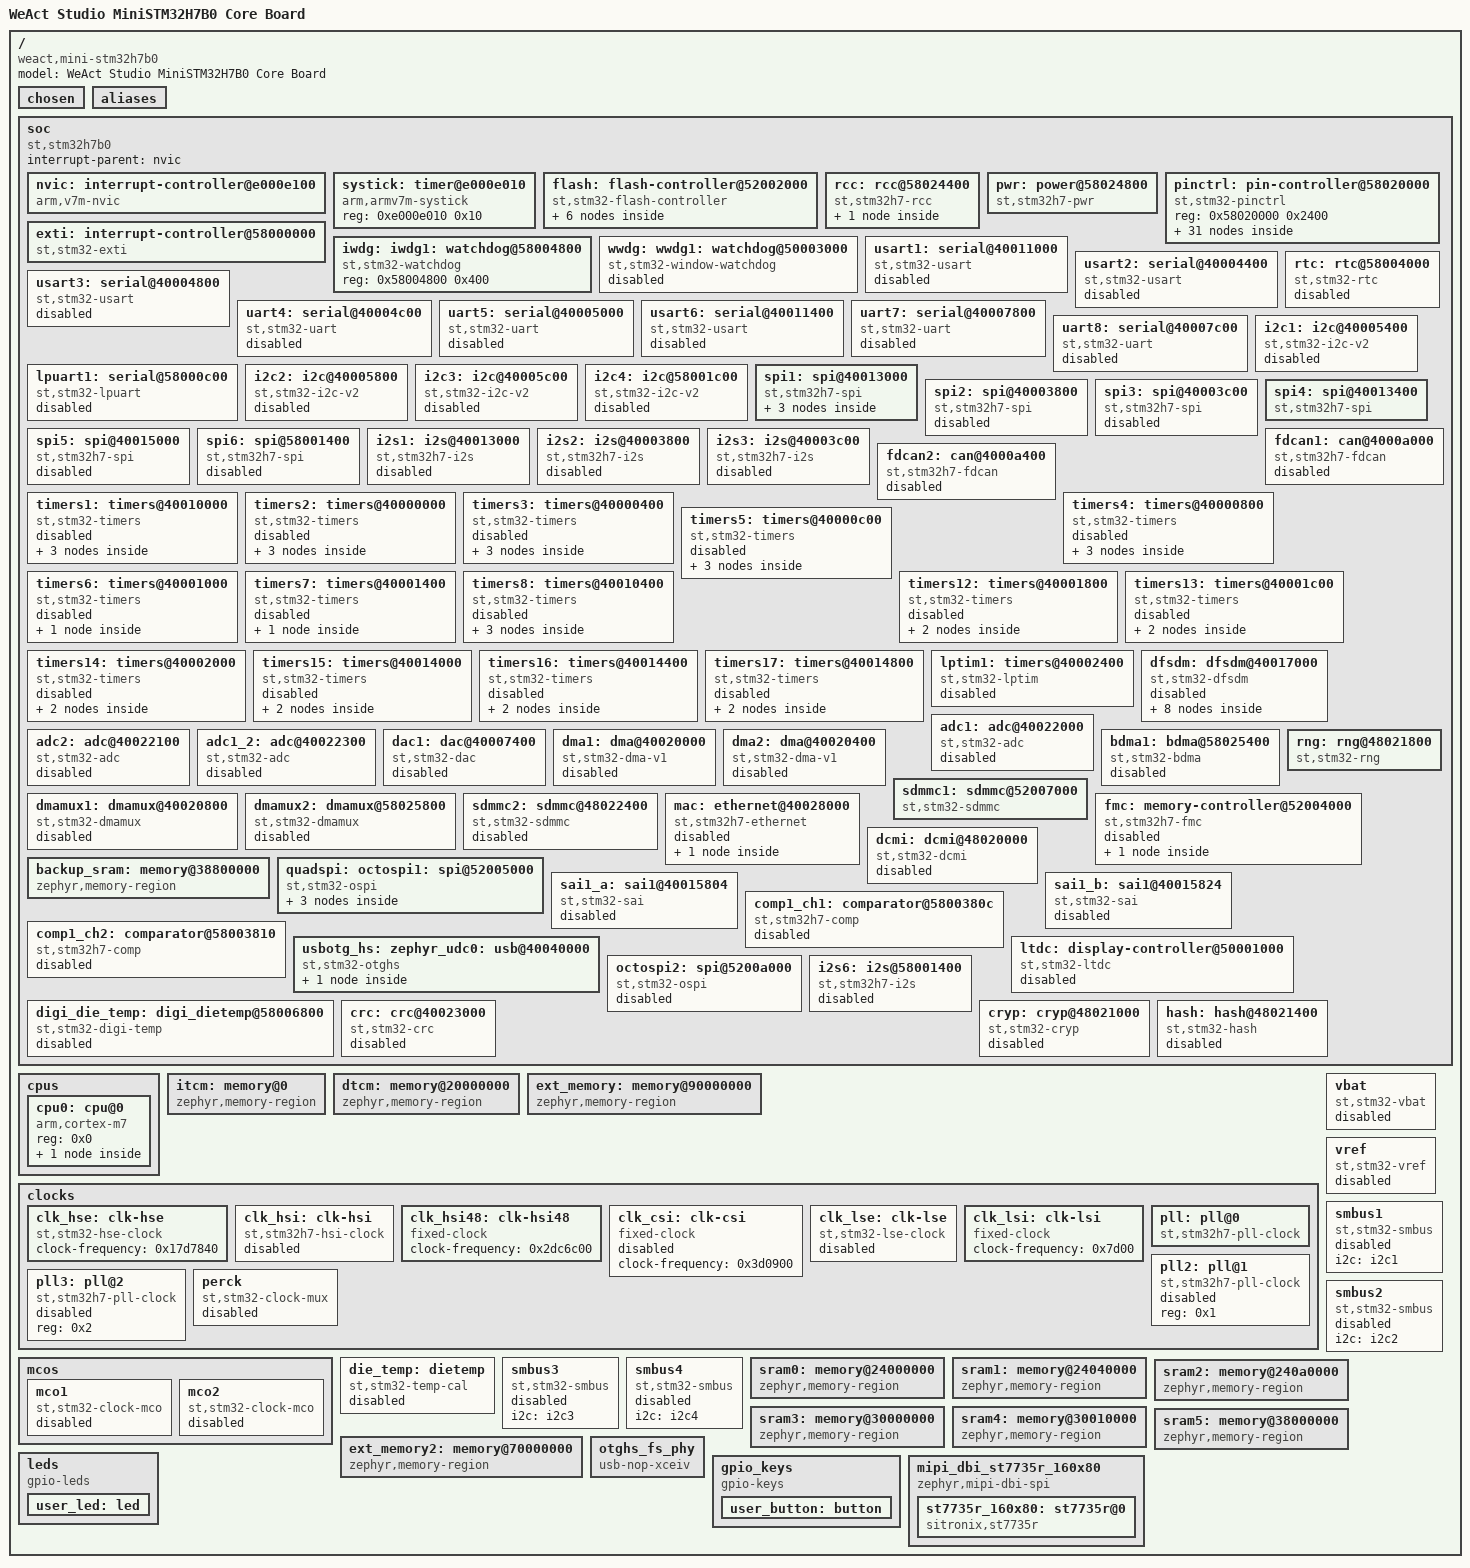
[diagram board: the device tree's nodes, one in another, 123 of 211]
/dts-v1/;

/* node '/' defined in zephyr/dts/common/skeleton.dtsi:9 */
/ {
	#address-cells = < 0x1 >;                        /* in zephyr/dts/common/skeleton.dtsi:10 */
	#size-cells = < 0x1 >;                           /* in zephyr/dts/common/skeleton.dtsi:11 */
	model = "WeAct Studio MiniSTM32H7B0 Core Board"; /* in zephyr/boards/weact/mini_stm32h7b0/mini_stm32h7b0.dts:14 */
	compatible = "weact,mini-stm32h7b0";             /* in zephyr/boards/weact/mini_stm32h7b0/mini_stm32h7b0.dts:15 */

	/* node '/chosen' defined in zephyr/dts/common/skeleton.dtsi:13 */
	chosen {
		zephyr,crc = &crc;                        /* in zephyr/dts/arm/st/h7/stm32h7.dtsi:29 */
		zephyr,entropy = &rng;                    /* in zephyr/dts/arm/st/h7/stm32h7.dtsi:30 */
		zephyr,flash-controller = &flash;         /* in zephyr/dts/arm/st/h7/stm32h7.dtsi:31 */
		zephyr,sram = &sram0;                     /* in zephyr/boards/weact/mini_stm32h7b0/mini_stm32h7b0.dts:18 */
		zephyr,flash = &flash0;                   /* in zephyr/boards/weact/mini_stm32h7b0/mini_stm32h7b0.dts:19 */
		zephyr,display = &st7735r_160x80;         /* in zephyr/boards/weact/mini_stm32h7b0/mini_stm32h7b0.dts:20 */
		zephyr,console = &board_cdc_acm_uart;     /* in zephyr/boards/common/usb/cdc_acm_serial.dtsi:9 */
		zephyr,shell-uart = &board_cdc_acm_uart;  /* in zephyr/boards/common/usb/cdc_acm_serial.dtsi:10 */
		zephyr,uart-mcumgr = &board_cdc_acm_uart; /* in zephyr/boards/common/usb/cdc_acm_serial.dtsi:11 */
		zephyr,bt-mon-uart = &board_cdc_acm_uart; /* in zephyr/boards/common/usb/cdc_acm_serial.dtsi:12 */
		zephyr,bt-c2h-uart = &board_cdc_acm_uart; /* in zephyr/boards/common/usb/cdc_acm_serial.dtsi:13 */
	};

	/* node '/aliases' defined in zephyr/dts/common/skeleton.dtsi:15 */
	aliases {
		led0 = &user_led;   /* in zephyr/boards/weact/mini_stm32h7b0/mini_stm32h7b0.dts:81 */
		sw0 = &user_button; /* in zephyr/boards/weact/mini_stm32h7b0/mini_stm32h7b0.dts:82 */
		watchdog0 = &iwdg;  /* in zephyr/boards/weact/mini_stm32h7b0/mini_stm32h7b0.dts:83 */
		sdhc0 = &sdmmc1;    /* in zephyr/boards/weact/mini_stm32h7b0/mini_stm32h7b0.dts:84 */
	};

	/* node '/soc' defined in zephyr/dts/arm/armv7-m.dtsi:6 */
	soc {
		#address-cells = < 0x1 >;     /* in zephyr/dts/arm/armv7-m.dtsi:7 */
		#size-cells = < 0x1 >;        /* in zephyr/dts/arm/armv7-m.dtsi:8 */
		interrupt-parent = < &nvic >; /* in zephyr/dts/arm/armv7-m.dtsi:10 */
		ranges;                       /* in zephyr/dts/arm/armv7-m.dtsi:11 */
		compatible = "st,stm32h7b0",
		             "st,stm32h7",
		             "simple-bus";    /* in zephyr/dts/arm/st/h7/stm32h7b0.dtsi:15 */

		/* node '/soc/interrupt-controller@e000e100' defined in zephyr/dts/arm/armv7-m.dtsi:13 */
		nvic: interrupt-controller@e000e100 {
			#address-cells = < 0x1 >;            /* in zephyr/dts/arm/armv7-m.dtsi:14 */
			compatible = "arm,v7m-nvic";         /* in zephyr/dts/arm/armv7-m.dtsi:15 */
			reg = < 0xe000e100 0xc00 >;          /* in zephyr/dts/arm/armv7-m.dtsi:16 */
			interrupt-controller;                /* in zephyr/dts/arm/armv7-m.dtsi:17 */
			#interrupt-cells = < 0x2 >;          /* in zephyr/dts/arm/armv7-m.dtsi:18 */
			arm,num-irq-priority-bits = < 0x4 >; /* in zephyr/dts/arm/st/h7/stm32h7.dtsi:1404 */
			phandle = < 0x1 >;                   /* in zephyr/dts/arm/armv7-m.dtsi:10 */
		};

		/* node '/soc/timer@e000e010' defined in zephyr/dts/arm/armv7-m.dtsi:21 */
		systick: timer@e000e010 {
			compatible = "arm,armv7m-systick"; /* in zephyr/dts/arm/armv7-m.dtsi:22 */
			reg = < 0xe000e010 0x10 >;         /* in zephyr/dts/arm/armv7-m.dtsi:23 */
		};

		/* node '/soc/flash-controller@52002000' defined in zephyr/dts/arm/st/h7/stm32h7.dtsi:162 */
		flash: flash-controller@52002000 {
			compatible = "st,stm32-flash-controller",
			             "st,stm32h7-flash-controller"; /* in zephyr/dts/arm/st/h7/stm32h7.dtsi:163 */
			reg = < 0x52002000 0x400 >;                 /* in zephyr/dts/arm/st/h7/stm32h7.dtsi:164 */
			interrupts = < 0x4 0x0 >;                   /* in zephyr/dts/arm/st/h7/stm32h7.dtsi:165 */
			#address-cells = < 0x1 >;                   /* in zephyr/dts/arm/st/h7/stm32h7.dtsi:167 */
			#size-cells = < 0x1 >;                      /* in zephyr/dts/arm/st/h7/stm32h7.dtsi:168 */
			ranges;                                     /* in zephyr/dts/arm/st/h7/stm32h7.dtsi:169 */

			/* node '/soc/flash-controller@52002000/flash@8000000' defined in zephyr/dts/arm/st/h7/stm32h7a3.dtsi:19 */
			flash0: flash@8000000 {
				compatible = "st,stm32-nv-flash",
				             "soc-nv-flash";        /* in zephyr/dts/arm/st/h7/stm32h7a3.dtsi:20 */
				#address-cells = < 0x1 >;           /* in zephyr/dts/arm/st/h7/stm32h7a3.dtsi:21 */
				#size-cells = < 0x1 >;              /* in zephyr/dts/arm/st/h7/stm32h7a3.dtsi:22 */
				write-block-size = < 0x10 >;        /* in zephyr/dts/arm/st/h7/stm32h7a3.dtsi:23 */
				erase-block-size = < 0x2000 >;      /* in zephyr/dts/arm/st/h7/stm32h7a3.dtsi:24 */
				max-erase-time = < 0x3 >;           /* in zephyr/dts/arm/st/h7/stm32h7a3.dtsi:26 */
				reg = < 0x8000000 0x20000 >;        /* in zephyr/dts/arm/st/h7/stm32h7b0Xb.dtsi:13 */
				ranges = < 0x0 0x8000000 0x20000 >; /* in zephyr/dts/arm/st/h7/stm32h7b0Xb.dtsi:14 */
			};

			/* node '/soc/flash-controller@52002000/flash@8fff800' defined in zephyr/dts/arm/st/h7/stm32h7a3.dtsi:36 */
			flash@8fff800 {
				compatible = "st,stm32-nvm-otp"; /* in zephyr/dts/arm/st/h7/stm32h7a3.dtsi:37 */
				reg = < 0x8fff800 0x200 >;       /* in zephyr/dts/arm/st/h7/stm32h7a3.dtsi:38 */

				/* node '/soc/flash-controller@52002000/flash@8fff800/nvmem-layout' defined in zephyr/dts/arm/st/h7/stm32h7a3.dtsi:40 */
				nvmem-layout {
					compatible = "fixed-layout"; /* in zephyr/dts/arm/st/h7/stm32h7a3.dtsi:41 */
					#address-cells = < 0x1 >;    /* in zephyr/dts/arm/st/h7/stm32h7a3.dtsi:42 */
					#size-cells = < 0x1 >;       /* in zephyr/dts/arm/st/h7/stm32h7a3.dtsi:43 */

					/* node '/soc/flash-controller@52002000/flash@8fff800/nvmem-layout/vrefint@10' defined in zephyr/dts/arm/st/h7/stm32h7a3.dtsi:45 */
					vrefint_otp: vrefint@10 {
						reg = < 0x10 0x2 >;          /* in zephyr/dts/arm/st/h7/stm32h7a3.dtsi:46 */
						#nvmem-cell-cells = < 0x0 >; /* in zephyr/dts/arm/st/h7/stm32h7a3.dtsi:47 */
						read-only;                   /* in zephyr/dts/arm/st/h7/stm32h7a3.dtsi:48 */
						phandle = < 0x23 >;          /* in zephyr/dts/arm/st/h7/stm32h7.dtsi:1364 */
					};

					/* node '/soc/flash-controller@52002000/flash@8fff800/nvmem-layout/ts-cal1@14' defined in zephyr/dts/arm/st/h7/stm32h7a3.dtsi:51 */
					ts_cal1_otp: ts-cal1@14 {
						reg = < 0x14 0x2 >;          /* in zephyr/dts/arm/st/h7/stm32h7a3.dtsi:52 */
						#nvmem-cell-cells = < 0x0 >; /* in zephyr/dts/arm/st/h7/stm32h7a3.dtsi:53 */
						read-only;                   /* in zephyr/dts/arm/st/h7/stm32h7a3.dtsi:54 */
						phandle = < 0x20 >;          /* in zephyr/dts/arm/st/h7/stm32h7.dtsi:1346 */
					};

					/* node '/soc/flash-controller@52002000/flash@8fff800/nvmem-layout/ts-cal2@18' defined in zephyr/dts/arm/st/h7/stm32h7a3.dtsi:57 */
					ts_cal2_otp: ts-cal2@18 {
						reg = < 0x18 0x2 >;          /* in zephyr/dts/arm/st/h7/stm32h7a3.dtsi:58 */
						#nvmem-cell-cells = < 0x0 >; /* in zephyr/dts/arm/st/h7/stm32h7a3.dtsi:59 */
						read-only;                   /* in zephyr/dts/arm/st/h7/stm32h7a3.dtsi:60 */
						phandle = < 0x21 >;          /* in zephyr/dts/arm/st/h7/stm32h7.dtsi:1346 */
					};
				};
			};
		};

		/* node '/soc/rcc@58024400' defined in zephyr/dts/arm/st/h7/stm32h7.dtsi:205 */
		rcc: rcc@58024400 {
			compatible = "st,stm32h7-rcc";    /* in zephyr/dts/arm/st/h7/stm32h7.dtsi:206 */
			#clock-cells = < 0x2 >;           /* in zephyr/dts/arm/st/h7/stm32h7.dtsi:207 */
			reg = < 0x58024400 0x400 >;       /* in zephyr/dts/arm/st/h7/stm32h7.dtsi:208 */
			clocks = < &pll >;                /* in zephyr/boards/weact/mini_stm32h7b0/mini_stm32h7b0.dts:112 */
			clock-frequency = < 0x10b07600 >; /* in zephyr/boards/weact/mini_stm32h7b0/mini_stm32h7b0.dts:113 */
			d1cpre = < 0x1 >;                 /* in zephyr/boards/weact/mini_stm32h7b0/mini_stm32h7b0.dts:114 */
			hpre = < 0x2 >;                   /* in zephyr/boards/weact/mini_stm32h7b0/mini_stm32h7b0.dts:115 */
			d1ppre = < 0x1 >;                 /* in zephyr/boards/weact/mini_stm32h7b0/mini_stm32h7b0.dts:116 */
			d2ppre1 = < 0x1 >;                /* in zephyr/boards/weact/mini_stm32h7b0/mini_stm32h7b0.dts:117 */
			d2ppre2 = < 0x1 >;                /* in zephyr/boards/weact/mini_stm32h7b0/mini_stm32h7b0.dts:118 */
			d3ppre = < 0x1 >;                 /* in zephyr/boards/weact/mini_stm32h7b0/mini_stm32h7b0.dts:119 */
			phandle = < 0x3 >;                /* in zephyr/dts/arm/st/h7/stm32h7.dtsi:231 */

			/* node '/soc/rcc@58024400/reset-controller' defined in zephyr/dts/arm/st/h7/stm32h7.dtsi:210 */
			rctl: reset-controller {
				compatible = "st,stm32-rcc-rctl"; /* in zephyr/dts/arm/st/h7/stm32h7.dtsi:211 */
				#reset-cells = < 0x1 >;           /* in zephyr/dts/arm/st/h7/stm32h7.dtsi:212 */
				phandle = < 0x4 >;                /* in zephyr/dts/arm/st/h7/stm32h7.dtsi:354 */
			};
		};

		/* node '/soc/power@58024800' defined in zephyr/dts/arm/st/h7/stm32h7.dtsi:216 */
		pwr: power@58024800 {
			compatible = "st,stm32h7-pwr"; /* in zephyr/dts/arm/st/h7/stm32h7.dtsi:221 */
			reg = < 0x58024800 0x400 >;    /* in zephyr/dts/arm/st/h7/stm32h7.dtsi:222 */
			power-supply = "ldo";          /* in zephyr/boards/weact/mini_stm32h7b0/mini_stm32h7b0.dts:123 */
		};

		/* node '/soc/interrupt-controller@58000000' defined in zephyr/dts/arm/st/h7/stm32h7.dtsi:225 */
		exti: interrupt-controller@58000000 {
			compatible = "st,stm32-exti";  /* in zephyr/dts/arm/st/h7/stm32h7.dtsi:226 */
			interrupt-controller;          /* in zephyr/dts/arm/st/h7/stm32h7.dtsi:227 */
			#interrupt-cells = < 0x1 >;    /* in zephyr/dts/arm/st/h7/stm32h7.dtsi:228 */
			#address-cells = < 0x0 >;      /* in zephyr/dts/arm/st/h7/stm32h7.dtsi:229 */
			reg = < 0x58000000 0x400 >;    /* in zephyr/dts/arm/st/h7/stm32h7.dtsi:230 */
			clocks = < &rcc 0xf4 0x2 >;    /* in zephyr/dts/arm/st/h7/stm32h7.dtsi:231 */
			num-lines = < 0x60 >;          /* in zephyr/dts/arm/st/h7/stm32h7.dtsi:232 */
			interrupts = < 0x6 0x0 >,
			             < 0x7 0x0 >,
			             < 0x8 0x0 >,
			             < 0x9 0x0 >,
			             < 0xa 0x0 >,
			             < 0x17 0x0 >,
			             < 0x28 0x0 >;     /* in zephyr/dts/arm/st/h7/stm32h7.dtsi:233 */
			interrupt-names = "line0",
			                  "line1",
			                  "line2",
			                  "line3",
			                  "line4",
			                  "line5-9",
			                  "line10-15"; /* in zephyr/dts/arm/st/h7/stm32h7.dtsi:235 */
			line-ranges = < 0x0 0x1 >,
			              < 0x1 0x1 >,
			              < 0x2 0x1 >,
			              < 0x3 0x1 >,
			              < 0x4 0x1 >,
			              < 0x5 0x5 >,
			              < 0xa 0x6 >;     /* in zephyr/dts/arm/st/h7/stm32h7.dtsi:237 */
		};

		/* node '/soc/pin-controller@58020000' defined in zephyr/dts/arm/st/h7/stm32h7.dtsi:241 */
		pinctrl: pin-controller@58020000 {
			compatible = "st,stm32-pinctrl"; /* in zephyr/dts/arm/st/h7/stm32h7.dtsi:242 */
			#address-cells = < 0x1 >;        /* in zephyr/dts/arm/st/h7/stm32h7.dtsi:243 */
			#size-cells = < 0x1 >;           /* in zephyr/dts/arm/st/h7/stm32h7.dtsi:244 */
			reg = < 0x58020000 0x2400 >;     /* in zephyr/dts/arm/st/h7/stm32h7.dtsi:245 */

			/* node '/soc/pin-controller@58020000/gpio@58020000' defined in zephyr/dts/arm/st/h7/stm32h7.dtsi:247 */
			gpioa: gpio@58020000 {
				compatible = "st,stm32-gpio"; /* in zephyr/dts/arm/st/h7/stm32h7.dtsi:248 */
				gpio-controller;              /* in zephyr/dts/arm/st/h7/stm32h7.dtsi:249 */
				#gpio-cells = < 0x2 >;        /* in zephyr/dts/arm/st/h7/stm32h7.dtsi:250 */
				reg = < 0x58020000 0x400 >;   /* in zephyr/dts/arm/st/h7/stm32h7.dtsi:251 */
				clocks = < &rcc 0xe0 0x1 >;   /* in zephyr/dts/arm/st/h7/stm32h7.dtsi:252 */
			};

			/* node '/soc/pin-controller@58020000/gpio@58020400' defined in zephyr/dts/arm/st/h7/stm32h7.dtsi:255 */
			gpiob: gpio@58020400 {
				compatible = "st,stm32-gpio"; /* in zephyr/dts/arm/st/h7/stm32h7.dtsi:256 */
				gpio-controller;              /* in zephyr/dts/arm/st/h7/stm32h7.dtsi:257 */
				#gpio-cells = < 0x2 >;        /* in zephyr/dts/arm/st/h7/stm32h7.dtsi:258 */
				reg = < 0x58020400 0x400 >;   /* in zephyr/dts/arm/st/h7/stm32h7.dtsi:259 */
				clocks = < &rcc 0xe0 0x2 >;   /* in zephyr/dts/arm/st/h7/stm32h7.dtsi:260 */
			};

			/* node '/soc/pin-controller@58020000/gpio@58020800' defined in zephyr/dts/arm/st/h7/stm32h7.dtsi:263 */
			gpioc: gpio@58020800 {
				compatible = "st,stm32-gpio"; /* in zephyr/dts/arm/st/h7/stm32h7.dtsi:264 */
				gpio-controller;              /* in zephyr/dts/arm/st/h7/stm32h7.dtsi:265 */
				#gpio-cells = < 0x2 >;        /* in zephyr/dts/arm/st/h7/stm32h7.dtsi:266 */
				reg = < 0x58020800 0x400 >;   /* in zephyr/dts/arm/st/h7/stm32h7.dtsi:267 */
				clocks = < &rcc 0xe0 0x4 >;   /* in zephyr/dts/arm/st/h7/stm32h7.dtsi:268 */
				phandle = < 0x28 >;           /* in zephyr/boards/weact/mini_stm32h7b0/mini_stm32h7b0.dts:37 */
			};

			/* node '/soc/pin-controller@58020000/gpio@58020c00' defined in zephyr/dts/arm/st/h7/stm32h7.dtsi:271 */
			gpiod: gpio@58020c00 {
				compatible = "st,stm32-gpio"; /* in zephyr/dts/arm/st/h7/stm32h7.dtsi:272 */
				gpio-controller;              /* in zephyr/dts/arm/st/h7/stm32h7.dtsi:273 */
				#gpio-cells = < 0x2 >;        /* in zephyr/dts/arm/st/h7/stm32h7.dtsi:274 */
				reg = < 0x58020c00 0x400 >;   /* in zephyr/dts/arm/st/h7/stm32h7.dtsi:275 */
				clocks = < &rcc 0xe0 0x8 >;   /* in zephyr/dts/arm/st/h7/stm32h7.dtsi:276 */
				phandle = < 0x8 >;            /* in zephyr/boards/weact/mini_stm32h7b0/mini_stm32h7b0.dts:175 */
			};

			/* node '/soc/pin-controller@58020000/gpio@58021000' defined in zephyr/dts/arm/st/h7/stm32h7.dtsi:279 */
			gpioe: gpio@58021000 {
				compatible = "st,stm32-gpio"; /* in zephyr/dts/arm/st/h7/stm32h7.dtsi:280 */
				gpio-controller;              /* in zephyr/dts/arm/st/h7/stm32h7.dtsi:281 */
				#gpio-cells = < 0x2 >;        /* in zephyr/dts/arm/st/h7/stm32h7.dtsi:282 */
				reg = < 0x58021000 0x400 >;   /* in zephyr/dts/arm/st/h7/stm32h7.dtsi:283 */
				clocks = < &rcc 0xe0 0x10 >;  /* in zephyr/dts/arm/st/h7/stm32h7.dtsi:284 */
				status = "okay";              /* in zephyr/boards/weact/mini_stm32h7b0/mini_stm32h7b0.dts:204 */
				phandle = < 0xb >;            /* in zephyr/boards/weact/mini_stm32h7b0/mini_stm32h7b0.dts:215 */

				/* node '/soc/pin-controller@58020000/gpio@58021000/lcd_led' defined in zephyr/boards/weact/mini_stm32h7b0/mini_stm32h7b0.dts:206 */
				lcd_led {
					gpio-hog;            /* in zephyr/boards/weact/mini_stm32h7b0/mini_stm32h7b0.dts:207 */
					gpios = < 0xa 0x1 >; /* in zephyr/boards/weact/mini_stm32h7b0/mini_stm32h7b0.dts:208 */
					output-high;         /* in zephyr/boards/weact/mini_stm32h7b0/mini_stm32h7b0.dts:209 */
				};
			};

			/* node '/soc/pin-controller@58020000/gpio@58021400' defined in zephyr/dts/arm/st/h7/stm32h7.dtsi:287 */
			gpiof: gpio@58021400 {
				compatible = "st,stm32-gpio"; /* in zephyr/dts/arm/st/h7/stm32h7.dtsi:288 */
				gpio-controller;              /* in zephyr/dts/arm/st/h7/stm32h7.dtsi:289 */
				#gpio-cells = < 0x2 >;        /* in zephyr/dts/arm/st/h7/stm32h7.dtsi:290 */
				reg = < 0x58021400 0x400 >;   /* in zephyr/dts/arm/st/h7/stm32h7.dtsi:291 */
				clocks = < &rcc 0xe0 0x20 >;  /* in zephyr/dts/arm/st/h7/stm32h7.dtsi:292 */
			};

			/* node '/soc/pin-controller@58020000/gpio@58021800' defined in zephyr/dts/arm/st/h7/stm32h7.dtsi:295 */
			gpiog: gpio@58021800 {
				compatible = "st,stm32-gpio"; /* in zephyr/dts/arm/st/h7/stm32h7.dtsi:296 */
				gpio-controller;              /* in zephyr/dts/arm/st/h7/stm32h7.dtsi:297 */
				#gpio-cells = < 0x2 >;        /* in zephyr/dts/arm/st/h7/stm32h7.dtsi:298 */
				reg = < 0x58021800 0x400 >;   /* in zephyr/dts/arm/st/h7/stm32h7.dtsi:299 */
				clocks = < &rcc 0xe0 0x40 >;  /* in zephyr/dts/arm/st/h7/stm32h7.dtsi:300 */
			};

			/* node '/soc/pin-controller@58020000/gpio@58021c00' defined in zephyr/dts/arm/st/h7/stm32h7.dtsi:303 */
			gpioh: gpio@58021c00 {
				compatible = "st,stm32-gpio"; /* in zephyr/dts/arm/st/h7/stm32h7.dtsi:304 */
				gpio-controller;              /* in zephyr/dts/arm/st/h7/stm32h7.dtsi:305 */
				#gpio-cells = < 0x2 >;        /* in zephyr/dts/arm/st/h7/stm32h7.dtsi:306 */
				reg = < 0x58021c00 0x400 >;   /* in zephyr/dts/arm/st/h7/stm32h7.dtsi:307 */
				clocks = < &rcc 0xe0 0x80 >;  /* in zephyr/dts/arm/st/h7/stm32h7.dtsi:308 */
			};

			/* node '/soc/pin-controller@58020000/gpio@58022000' defined in zephyr/dts/arm/st/h7/stm32h7.dtsi:311 */
			gpioi: gpio@58022000 {
				compatible = "st,stm32-gpio"; /* in zephyr/dts/arm/st/h7/stm32h7.dtsi:312 */
				gpio-controller;              /* in zephyr/dts/arm/st/h7/stm32h7.dtsi:313 */
				#gpio-cells = < 0x2 >;        /* in zephyr/dts/arm/st/h7/stm32h7.dtsi:314 */
				reg = < 0x58022000 0x400 >;   /* in zephyr/dts/arm/st/h7/stm32h7.dtsi:315 */
				clocks = < &rcc 0xe0 0x100 >; /* in zephyr/dts/arm/st/h7/stm32h7.dtsi:316 */
			};

			/* node '/soc/pin-controller@58020000/gpio@58022400' defined in zephyr/dts/arm/st/h7/stm32h7.dtsi:319 */
			gpioj: gpio@58022400 {
				compatible = "st,stm32-gpio"; /* in zephyr/dts/arm/st/h7/stm32h7.dtsi:320 */
				gpio-controller;              /* in zephyr/dts/arm/st/h7/stm32h7.dtsi:321 */
				#gpio-cells = < 0x2 >;        /* in zephyr/dts/arm/st/h7/stm32h7.dtsi:322 */
				reg = < 0x58022400 0x400 >;   /* in zephyr/dts/arm/st/h7/stm32h7.dtsi:323 */
				clocks = < &rcc 0xe0 0x200 >; /* in zephyr/dts/arm/st/h7/stm32h7.dtsi:324 */
			};

			/* node '/soc/pin-controller@58020000/gpio@58022800' defined in zephyr/dts/arm/st/h7/stm32h7.dtsi:327 */
			gpiok: gpio@58022800 {
				compatible = "st,stm32-gpio"; /* in zephyr/dts/arm/st/h7/stm32h7.dtsi:328 */
				gpio-controller;              /* in zephyr/dts/arm/st/h7/stm32h7.dtsi:329 */
				#gpio-cells = < 0x2 >;        /* in zephyr/dts/arm/st/h7/stm32h7.dtsi:330 */
				reg = < 0x58022800 0x400 >;   /* in zephyr/dts/arm/st/h7/stm32h7.dtsi:331 */
				clocks = < &rcc 0xe0 0x400 >; /* in zephyr/dts/arm/st/h7/stm32h7.dtsi:332 */
			};

			/* node '/soc/pin-controller@58020000/octospim_p1_clk_pb2' defined in modules/hal/stm32/dts/st/h7/stm32h7b0vbtx-pinctrl.dtsi:1997 */
			octospim_p1_clk_pb2: octospim_p1_clk_pb2 {
				pinmux = < 0x249 >;            /* in modules/hal/stm32/dts/st/h7/stm32h7b0vbtx-pinctrl.dtsi:1998 */
				slew-rate = "very-high-speed"; /* in modules/hal/stm32/dts/st/h7/stm32h7b0vbtx-pinctrl.dtsi:1999 */
				phandle = < 0x14 >;            /* in zephyr/boards/weact/mini_stm32h7b0/mini_stm32h7b0.dts:146 */
			};

			/* node '/soc/pin-controller@58020000/octospim_p1_ncs_pb6' defined in modules/hal/stm32/dts/st/h7/stm32h7b0vbtx-pinctrl.dtsi:2007 */
			octospim_p1_ncs_pb6: octospim_p1_ncs_pb6 {
				pinmux = < 0x2ca >;            /* in modules/hal/stm32/dts/st/h7/stm32h7b0vbtx-pinctrl.dtsi:2008 */
				slew-rate = "very-high-speed"; /* in modules/hal/stm32/dts/st/h7/stm32h7b0vbtx-pinctrl.dtsi:2009 */
				phandle = < 0x15 >;            /* in zephyr/boards/weact/mini_stm32h7b0/mini_stm32h7b0.dts:146 */
			};

			/* node '/soc/pin-controller@58020000/octospim_p1_io0_pd11' defined in modules/hal/stm32/dts/st/h7/stm32h7b0vbtx-pinctrl.dtsi:2087 */
			octospim_p1_io0_pd11: octospim_p1_io0_pd11 {
				pinmux = < 0x769 >;            /* in modules/hal/stm32/dts/st/h7/stm32h7b0vbtx-pinctrl.dtsi:2088 */
				slew-rate = "very-high-speed"; /* in modules/hal/stm32/dts/st/h7/stm32h7b0vbtx-pinctrl.dtsi:2089 */
				phandle = < 0x16 >;            /* in zephyr/boards/weact/mini_stm32h7b0/mini_stm32h7b0.dts:146 */
			};

			/* node '/soc/pin-controller@58020000/octospim_p1_io1_pd12' defined in modules/hal/stm32/dts/st/h7/stm32h7b0vbtx-pinctrl.dtsi:2092 */
			octospim_p1_io1_pd12: octospim_p1_io1_pd12 {
				pinmux = < 0x789 >;            /* in modules/hal/stm32/dts/st/h7/stm32h7b0vbtx-pinctrl.dtsi:2093 */
				slew-rate = "very-high-speed"; /* in modules/hal/stm32/dts/st/h7/stm32h7b0vbtx-pinctrl.dtsi:2094 */
				phandle = < 0x17 >;            /* in zephyr/boards/weact/mini_stm32h7b0/mini_stm32h7b0.dts:146 */
			};

			/* node '/soc/pin-controller@58020000/octospim_p1_io3_pd13' defined in modules/hal/stm32/dts/st/h7/stm32h7b0vbtx-pinctrl.dtsi:2097 */
			octospim_p1_io3_pd13: octospim_p1_io3_pd13 {
				pinmux = < 0x7a9 >;            /* in modules/hal/stm32/dts/st/h7/stm32h7b0vbtx-pinctrl.dtsi:2098 */
				slew-rate = "very-high-speed"; /* in modules/hal/stm32/dts/st/h7/stm32h7b0vbtx-pinctrl.dtsi:2099 */
				phandle = < 0x19 >;            /* in zephyr/boards/weact/mini_stm32h7b0/mini_stm32h7b0.dts:146 */
			};

			/* node '/soc/pin-controller@58020000/octospim_p1_io2_pe2' defined in modules/hal/stm32/dts/st/h7/stm32h7b0vbtx-pinctrl.dtsi:2102 */
			octospim_p1_io2_pe2: octospim_p1_io2_pe2 {
				pinmux = < 0x849 >;            /* in modules/hal/stm32/dts/st/h7/stm32h7b0vbtx-pinctrl.dtsi:2103 */
				slew-rate = "very-high-speed"; /* in modules/hal/stm32/dts/st/h7/stm32h7b0vbtx-pinctrl.dtsi:2104 */
				phandle = < 0x18 >;            /* in zephyr/boards/weact/mini_stm32h7b0/mini_stm32h7b0.dts:146 */
			};

			/* node '/soc/pin-controller@58020000/sdmmc1_d0_pc8' defined in modules/hal/stm32/dts/st/h7/stm32h7b0vbtx-pinctrl.dtsi:2352 */
			sdmmc1_d0_pc8: sdmmc1_d0_pc8 {
				pinmux = < 0x50c >;            /* in modules/hal/stm32/dts/st/h7/stm32h7b0vbtx-pinctrl.dtsi:2353 */
				bias-pull-up;                  /* in modules/hal/stm32/dts/st/h7/stm32h7b0vbtx-pinctrl.dtsi:2354 */
				slew-rate = "very-high-speed"; /* in modules/hal/stm32/dts/st/h7/stm32h7b0vbtx-pinctrl.dtsi:2355 */
				phandle = < 0xd >;             /* in zephyr/boards/weact/mini_stm32h7b0/mini_stm32h7b0.dts:127 */
			};

			/* node '/soc/pin-controller@58020000/sdmmc1_d1_pc9' defined in modules/hal/stm32/dts/st/h7/stm32h7b0vbtx-pinctrl.dtsi:2358 */
			sdmmc1_d1_pc9: sdmmc1_d1_pc9 {
				pinmux = < 0x52c >;            /* in modules/hal/stm32/dts/st/h7/stm32h7b0vbtx-pinctrl.dtsi:2359 */
				bias-pull-up;                  /* in modules/hal/stm32/dts/st/h7/stm32h7b0vbtx-pinctrl.dtsi:2360 */
				slew-rate = "very-high-speed"; /* in modules/hal/stm32/dts/st/h7/stm32h7b0vbtx-pinctrl.dtsi:2361 */
				phandle = < 0xe >;             /* in zephyr/boards/weact/mini_stm32h7b0/mini_stm32h7b0.dts:127 */
			};

			/* node '/soc/pin-controller@58020000/sdmmc1_d2_pc10' defined in modules/hal/stm32/dts/st/h7/stm32h7b0vbtx-pinctrl.dtsi:2364 */
			sdmmc1_d2_pc10: sdmmc1_d2_pc10 {
				pinmux = < 0x54c >;            /* in modules/hal/stm32/dts/st/h7/stm32h7b0vbtx-pinctrl.dtsi:2365 */
				bias-pull-up;                  /* in modules/hal/stm32/dts/st/h7/stm32h7b0vbtx-pinctrl.dtsi:2366 */
				slew-rate = "very-high-speed"; /* in modules/hal/stm32/dts/st/h7/stm32h7b0vbtx-pinctrl.dtsi:2367 */
				phandle = < 0xf >;             /* in zephyr/boards/weact/mini_stm32h7b0/mini_stm32h7b0.dts:127 */
			};

			/* node '/soc/pin-controller@58020000/sdmmc1_d3_pc11' defined in modules/hal/stm32/dts/st/h7/stm32h7b0vbtx-pinctrl.dtsi:2370 */
			sdmmc1_d3_pc11: sdmmc1_d3_pc11 {
				pinmux = < 0x56c >;            /* in modules/hal/stm32/dts/st/h7/stm32h7b0vbtx-pinctrl.dtsi:2371 */
				bias-pull-up;                  /* in modules/hal/stm32/dts/st/h7/stm32h7b0vbtx-pinctrl.dtsi:2372 */
				slew-rate = "very-high-speed"; /* in modules/hal/stm32/dts/st/h7/stm32h7b0vbtx-pinctrl.dtsi:2373 */
				phandle = < 0x10 >;            /* in zephyr/boards/weact/mini_stm32h7b0/mini_stm32h7b0.dts:127 */
			};

			/* node '/soc/pin-controller@58020000/sdmmc1_ck_pc12' defined in modules/hal/stm32/dts/st/h7/stm32h7b0vbtx-pinctrl.dtsi:2376 */
			sdmmc1_ck_pc12: sdmmc1_ck_pc12 {
				pinmux = < 0x58c >;            /* in modules/hal/stm32/dts/st/h7/stm32h7b0vbtx-pinctrl.dtsi:2377 */
				bias-pull-up;                  /* in modules/hal/stm32/dts/st/h7/stm32h7b0vbtx-pinctrl.dtsi:2378 */
				slew-rate = "very-high-speed"; /* in modules/hal/stm32/dts/st/h7/stm32h7b0vbtx-pinctrl.dtsi:2379 */
				phandle = < 0x11 >;            /* in zephyr/boards/weact/mini_stm32h7b0/mini_stm32h7b0.dts:127 */
			};

			/* node '/soc/pin-controller@58020000/sdmmc1_cmd_pd2' defined in modules/hal/stm32/dts/st/h7/stm32h7b0vbtx-pinctrl.dtsi:2382 */
			sdmmc1_cmd_pd2: sdmmc1_cmd_pd2 {
				pinmux = < 0x64c >;            /* in modules/hal/stm32/dts/st/h7/stm32h7b0vbtx-pinctrl.dtsi:2383 */
				bias-pull-up;                  /* in modules/hal/stm32/dts/st/h7/stm32h7b0vbtx-pinctrl.dtsi:2384 */
				slew-rate = "very-high-speed"; /* in modules/hal/stm32/dts/st/h7/stm32h7b0vbtx-pinctrl.dtsi:2385 */
				phandle = < 0x12 >;            /* in zephyr/boards/weact/mini_stm32h7b0/mini_stm32h7b0.dts:127 */
			};

			/* node '/soc/pin-controller@58020000/spi1_miso_pb4' defined in modules/hal/stm32/dts/st/h7/stm32h7b0vbtx-pinctrl.dtsi:2468 */
			spi1_miso_pb4: spi1_miso_pb4 {
				pinmux = < 0x285 >;            /* in modules/hal/stm32/dts/st/h7/stm32h7b0vbtx-pinctrl.dtsi:2469 */
				bias-pull-down;                /* in modules/hal/stm32/dts/st/h7/stm32h7b0vbtx-pinctrl.dtsi:2470 */
				slew-rate = "very-high-speed"; /* in modules/hal/stm32/dts/st/h7/stm32h7b0vbtx-pinctrl.dtsi:2471 */
				phandle = < 0x6 >;             /* in zephyr/boards/weact/mini_stm32h7b0/mini_stm32h7b0.dts:174 */
			};

			/* node '/soc/pin-controller@58020000/spi1_mosi_pd7' defined in modules/hal/stm32/dts/st/h7/stm32h7b0vbtx-pinctrl.dtsi:2536 */
			spi1_mosi_pd7: spi1_mosi_pd7 {
				pinmux = < 0x6e5 >;            /* in modules/hal/stm32/dts/st/h7/stm32h7b0vbtx-pinctrl.dtsi:2537 */
				bias-pull-down;                /* in modules/hal/stm32/dts/st/h7/stm32h7b0vbtx-pinctrl.dtsi:2538 */
				slew-rate = "very-high-speed"; /* in modules/hal/stm32/dts/st/h7/stm32h7b0vbtx-pinctrl.dtsi:2539 */
				phandle = < 0x7 >;             /* in zephyr/boards/weact/mini_stm32h7b0/mini_stm32h7b0.dts:174 */
			};

			/* node '/soc/pin-controller@58020000/spi4_mosi_pe14' defined in modules/hal/stm32/dts/st/h7/stm32h7b0vbtx-pinctrl.dtsi:2590 */
			spi4_mosi_pe14: spi4_mosi_pe14 {
				pinmux = < 0x9c5 >;            /* in modules/hal/stm32/dts/st/h7/stm32h7b0vbtx-pinctrl.dtsi:2591 */
				bias-pull-down;                /* in modules/hal/stm32/dts/st/h7/stm32h7b0vbtx-pinctrl.dtsi:2592 */
				slew-rate = "very-high-speed"; /* in modules/hal/stm32/dts/st/h7/stm32h7b0vbtx-pinctrl.dtsi:2593 */
				phandle = < 0xa >;             /* in zephyr/boards/weact/mini_stm32h7b0/mini_stm32h7b0.dts:214 */
			};

			/* node '/soc/pin-controller@58020000/spi1_sck_pb3' defined in modules/hal/stm32/dts/st/h7/stm32h7b0vbtx-pinctrl.dtsi:2696 */
			spi1_sck_pb3: spi1_sck_pb3 {
				pinmux = < 0x265 >;            /* in modules/hal/stm32/dts/st/h7/stm32h7b0vbtx-pinctrl.dtsi:2697 */
				bias-pull-down;                /* in modules/hal/stm32/dts/st/h7/stm32h7b0vbtx-pinctrl.dtsi:2698 */
				slew-rate = "very-high-speed"; /* in modules/hal/stm32/dts/st/h7/stm32h7b0vbtx-pinctrl.dtsi:2699 */
				phandle = < 0x5 >;             /* in zephyr/boards/weact/mini_stm32h7b0/mini_stm32h7b0.dts:174 */
			};

			/* node '/soc/pin-controller@58020000/spi4_sck_pe12' defined in modules/hal/stm32/dts/st/h7/stm32h7b0vbtx-pinctrl.dtsi:2750 */
			spi4_sck_pe12: spi4_sck_pe12 {
				pinmux = < 0x985 >;            /* in modules/hal/stm32/dts/st/h7/stm32h7b0vbtx-pinctrl.dtsi:2751 */
				bias-pull-down;                /* in modules/hal/stm32/dts/st/h7/stm32h7b0vbtx-pinctrl.dtsi:2752 */
				slew-rate = "very-high-speed"; /* in modules/hal/stm32/dts/st/h7/stm32h7b0vbtx-pinctrl.dtsi:2753 */
				phandle = < 0x9 >;             /* in zephyr/boards/weact/mini_stm32h7b0/mini_stm32h7b0.dts:214 */
			};

			/* node '/soc/pin-controller@58020000/usb_otg_hs_dm_pa11' defined in modules/hal/stm32/dts/st/h7/stm32h7b0vbtx-pinctrl.dtsi:3543 */
			usb_otg_hs_dm_pa11: usb_otg_hs_dm_pa11 {
				pinmux = < 0x170 >; /* in modules/hal/stm32/dts/st/h7/stm32h7b0vbtx-pinctrl.dtsi:3544 */
				phandle = < 0x1c >; /* in zephyr/boards/weact/mini_stm32h7b0/mini_stm32h7b0.dts:137 */
			};

			/* node '/soc/pin-controller@58020000/usb_otg_hs_dp_pa12' defined in modules/hal/stm32/dts/st/h7/stm32h7b0vbtx-pinctrl.dtsi:3547 */
			usb_otg_hs_dp_pa12: usb_otg_hs_dp_pa12 {
				pinmux = < 0x190 >; /* in modules/hal/stm32/dts/st/h7/stm32h7b0vbtx-pinctrl.dtsi:3548 */
				phandle = < 0x1d >; /* in zephyr/boards/weact/mini_stm32h7b0/mini_stm32h7b0.dts:137 */
			};
		};

		/* node '/soc/watchdog@58004800' defined in zephyr/dts/arm/st/h7/stm32h7.dtsi:336 */
		iwdg: iwdg1: watchdog@58004800 {
			compatible = "st,stm32-watchdog"; /* in zephyr/dts/arm/st/h7/stm32h7.dtsi:337 */
			reg = < 0x58004800 0x400 >;       /* in zephyr/dts/arm/st/h7/stm32h7.dtsi:338 */
			status = "okay";                  /* in zephyr/boards/weact/mini_stm32h7b0/mini_stm32h7b0.dts:229 */
		};

		/* node '/soc/watchdog@50003000' defined in zephyr/dts/arm/st/h7/stm32h7.dtsi:342 */
		wwdg: wwdg1: watchdog@50003000 {
			compatible = "st,stm32-window-watchdog"; /* in zephyr/dts/arm/st/h7/stm32h7.dtsi:343 */
			reg = < 0x50003000 0x1000 >;             /* in zephyr/dts/arm/st/h7/stm32h7.dtsi:344 */
			clocks = < &rcc 0xe4 0x40 >;             /* in zephyr/dts/arm/st/h7/stm32h7.dtsi:345 */
			interrupts = < 0x0 0x0 >;                /* in zephyr/dts/arm/st/h7/stm32h7.dtsi:346 */
			status = "disabled";                     /* in zephyr/dts/arm/st/h7/stm32h7.dtsi:347 */
		};

		/* node '/soc/serial@40011000' defined in zephyr/dts/arm/st/h7/stm32h7.dtsi:350 */
		usart1: serial@40011000 {
			compatible = "st,stm32-usart",
			             "st,stm32-uart";  /* in zephyr/dts/arm/st/h7/stm32h7.dtsi:351 */
			reg = < 0x40011000 0x400 >;    /* in zephyr/dts/arm/st/h7/stm32h7.dtsi:352 */
			clocks = < &rcc 0xf0 0x10 >;   /* in zephyr/dts/arm/st/h7/stm32h7.dtsi:353 */
			resets = < &rctl 0x1304 >;     /* in zephyr/dts/arm/st/h7/stm32h7.dtsi:354 */
			interrupts = < 0x25 0x0 >;     /* in zephyr/dts/arm/st/h7/stm32h7.dtsi:355 */
			status = "disabled";           /* in zephyr/dts/arm/st/h7/stm32h7.dtsi:356 */
		};

		/* node '/soc/serial@40004400' defined in zephyr/dts/arm/st/h7/stm32h7.dtsi:359 */
		usart2: serial@40004400 {
			compatible = "st,stm32-usart",
			             "st,stm32-uart";   /* in zephyr/dts/arm/st/h7/stm32h7.dtsi:360 */
			reg = < 0x40004400 0x400 >;     /* in zephyr/dts/arm/st/h7/stm32h7.dtsi:361 */
			clocks = < &rcc 0xe8 0x20000 >; /* in zephyr/dts/arm/st/h7/stm32h7.dtsi:362 */
			resets = < &rctl 0x1211 >;      /* in zephyr/dts/arm/st/h7/stm32h7.dtsi:363 */
			interrupts = < 0x26 0x0 >;      /* in zephyr/dts/arm/st/h7/stm32h7.dtsi:364 */
			status = "disabled";            /* in zephyr/dts/arm/st/h7/stm32h7.dtsi:365 */
		};

		/* node '/soc/serial@40004800' defined in zephyr/dts/arm/st/h7/stm32h7.dtsi:368 */
		usart3: serial@40004800 {
			compatible = "st,stm32-usart",
			             "st,stm32-uart";   /* in zephyr/dts/arm/st/h7/stm32h7.dtsi:369 */
			reg = < 0x40004800 0x400 >;     /* in zephyr/dts/arm/st/h7/stm32h7.dtsi:370 */
			clocks = < &rcc 0xe8 0x40000 >; /* in zephyr/dts/arm/st/h7/stm32h7.dtsi:371 */
			resets = < &rctl 0x1212 >;      /* in zephyr/dts/arm/st/h7/stm32h7.dtsi:372 */
			interrupts = < 0x27 0x0 >;      /* in zephyr/dts/arm/st/h7/stm32h7.dtsi:373 */
			status = "disabled";            /* in zephyr/dts/arm/st/h7/stm32h7.dtsi:374 */
		};

		/* node '/soc/serial@40004c00' defined in zephyr/dts/arm/st/h7/stm32h7.dtsi:377 */
		uart4: serial@40004c00 {
			compatible = "st,stm32-uart";   /* in zephyr/dts/arm/st/h7/stm32h7.dtsi:378 */
			reg = < 0x40004c00 0x400 >;     /* in zephyr/dts/arm/st/h7/stm32h7.dtsi:379 */
			clocks = < &rcc 0xe8 0x80000 >; /* in zephyr/dts/arm/st/h7/stm32h7.dtsi:380 */
			resets = < &rctl 0x1213 >;      /* in zephyr/dts/arm/st/h7/stm32h7.dtsi:381 */
			interrupts = < 0x34 0x0 >;      /* in zephyr/dts/arm/st/h7/stm32h7.dtsi:382 */
			status = "disabled";            /* in zephyr/dts/arm/st/h7/stm32h7.dtsi:383 */
		};

		/* node '/soc/serial@40005000' defined in zephyr/dts/arm/st/h7/stm32h7.dtsi:386 */
		uart5: serial@40005000 {
			compatible = "st,stm32-uart";    /* in zephyr/dts/arm/st/h7/stm32h7.dtsi:387 */
			reg = < 0x40005000 0x400 >;      /* in zephyr/dts/arm/st/h7/stm32h7.dtsi:388 */
			clocks = < &rcc 0xe8 0x100000 >; /* in zephyr/dts/arm/st/h7/stm32h7.dtsi:389 */
			resets = < &rctl 0x1214 >;       /* in zephyr/dts/arm/st/h7/stm32h7.dtsi:390 */
			interrupts = < 0x35 0x0 >;       /* in zephyr/dts/arm/st/h7/stm32h7.dtsi:391 */
			status = "disabled";             /* in zephyr/dts/arm/st/h7/stm32h7.dtsi:392 */
		};

		/* node '/soc/serial@40011400' defined in zephyr/dts/arm/st/h7/stm32h7.dtsi:395 */
		usart6: serial@40011400 {
			compatible = "st,stm32-usart",
			             "st,stm32-uart";  /* in zephyr/dts/arm/st/h7/stm32h7.dtsi:396 */
			reg = < 0x40011400 0x400 >;    /* in zephyr/dts/arm/st/h7/stm32h7.dtsi:397 */
			clocks = < &rcc 0xf0 0x20 >;   /* in zephyr/dts/arm/st/h7/stm32h7.dtsi:398 */
			resets = < &rctl 0x1305 >;     /* in zephyr/dts/arm/st/h7/stm32h7.dtsi:399 */
			interrupts = < 0x47 0x0 >;     /* in zephyr/dts/arm/st/h7/stm32h7.dtsi:400 */
			status = "disabled";           /* in zephyr/dts/arm/st/h7/stm32h7.dtsi:401 */
		};

		/* node '/soc/serial@40007800' defined in zephyr/dts/arm/st/h7/stm32h7.dtsi:404 */
		uart7: serial@40007800 {
			compatible = "st,stm32-uart";      /* in zephyr/dts/arm/st/h7/stm32h7.dtsi:405 */
			reg = < 0x40007800 0x400 >;        /* in zephyr/dts/arm/st/h7/stm32h7.dtsi:406 */
			clocks = < &rcc 0xe8 0x40000000 >; /* in zephyr/dts/arm/st/h7/stm32h7.dtsi:407 */
			resets = < &rctl 0x121e >;         /* in zephyr/dts/arm/st/h7/stm32h7.dtsi:408 */
			interrupts = < 0x52 0x0 >;         /* in zephyr/dts/arm/st/h7/stm32h7.dtsi:409 */
			status = "disabled";               /* in zephyr/dts/arm/st/h7/stm32h7.dtsi:410 */
		};

		/* node '/soc/serial@40007c00' defined in zephyr/dts/arm/st/h7/stm32h7.dtsi:413 */
		uart8: serial@40007c00 {
			compatible = "st,stm32-uart";      /* in zephyr/dts/arm/st/h7/stm32h7.dtsi:414 */
			reg = < 0x40007c00 0x400 >;        /* in zephyr/dts/arm/st/h7/stm32h7.dtsi:415 */
			clocks = < &rcc 0xe8 0x80000000 >; /* in zephyr/dts/arm/st/h7/stm32h7.dtsi:416 */
			resets = < &rctl 0x121f >;         /* in zephyr/dts/arm/st/h7/stm32h7.dtsi:417 */
			interrupts = < 0x53 0x0 >;         /* in zephyr/dts/arm/st/h7/stm32h7.dtsi:418 */
			status = "disabled";               /* in zephyr/dts/arm/st/h7/stm32h7.dtsi:419 */
		};

		/* node '/soc/serial@58000c00' defined in zephyr/dts/arm/st/h7/stm32h7.dtsi:422 */
		lpuart1: serial@58000c00 {
			compatible = "st,stm32-lpuart",
			             "st,stm32-uart";   /* in zephyr/dts/arm/st/h7/stm32h7.dtsi:423 */
			reg = < 0x58000c00 0x400 >;     /* in zephyr/dts/arm/st/h7/stm32h7.dtsi:424 */
			clocks = < &rcc 0xf4 0x8 >;     /* in zephyr/dts/arm/st/h7/stm32h7.dtsi:425 */
			resets = < &rctl 0x1383 >;      /* in zephyr/dts/arm/st/h7/stm32h7.dtsi:426 */
			interrupts = < 0x8e 0x0 >;      /* in zephyr/dts/arm/st/h7/stm32h7.dtsi:427 */
			status = "disabled";            /* in zephyr/dts/arm/st/h7/stm32h7.dtsi:428 */
		};

		/* node '/soc/rtc@58004000' defined in zephyr/dts/arm/st/h7/stm32h7.dtsi:431 */
		rtc: rtc@58004000 {
			compatible = "st,stm32-rtc";    /* in zephyr/dts/arm/st/h7/stm32h7.dtsi:432 */
			reg = < 0x58004000 0x400 >;     /* in zephyr/dts/arm/st/h7/stm32h7.dtsi:433 */
			interrupts = < 0x29 0x0 >;      /* in zephyr/dts/arm/st/h7/stm32h7.dtsi:434 */
			clocks = < &rcc 0xf4 0x10000 >; /* in zephyr/dts/arm/st/h7/stm32h7.dtsi:435 */
			prescaler = < 0x8000 >;         /* in zephyr/dts/arm/st/h7/stm32h7.dtsi:436 */
			alarms-count = < 0x2 >;         /* in zephyr/dts/arm/st/h7/stm32h7.dtsi:437 */
			alrm-exti-line = < 0x11 >;      /* in zephyr/dts/arm/st/h7/stm32h7.dtsi:438 */
			status = "disabled";            /* in zephyr/dts/arm/st/h7/stm32h7.dtsi:439 */
		};

		/* node '/soc/i2c@40005400' defined in zephyr/dts/arm/st/h7/stm32h7.dtsi:442 */
		i2c1: i2c@40005400 {
			compatible = "st,stm32-i2c-v2";  /* in zephyr/dts/arm/st/h7/stm32h7.dtsi:443 */
			clock-frequency = < 0x186a0 >;   /* in zephyr/dts/arm/st/h7/stm32h7.dtsi:444 */
			#address-cells = < 0x1 >;        /* in zephyr/dts/arm/st/h7/stm32h7.dtsi:445 */
			#size-cells = < 0x0 >;           /* in zephyr/dts/arm/st/h7/stm32h7.dtsi:446 */
			reg = < 0x40005400 0x400 >;      /* in zephyr/dts/arm/st/h7/stm32h7.dtsi:447 */
			clocks = < &rcc 0xe8 0x200000 >; /* in zephyr/dts/arm/st/h7/stm32h7.dtsi:448 */
			interrupts = < 0x1f 0x0 >,
			             < 0x20 0x0 >;       /* in zephyr/dts/arm/st/h7/stm32h7.dtsi:449 */
			interrupt-names = "event",
			                  "error";       /* in zephyr/dts/arm/st/h7/stm32h7.dtsi:450 */
			status = "disabled";             /* in zephyr/dts/arm/st/h7/stm32h7.dtsi:451 */
			phandle = < 0x24 >;              /* in zephyr/dts/arm/st/h7/stm32h7.dtsi:1374 */
		};

		/* node '/soc/i2c@40005800' defined in zephyr/dts/arm/st/h7/stm32h7.dtsi:454 */
		i2c2: i2c@40005800 {
			compatible = "st,stm32-i2c-v2";  /* in zephyr/dts/arm/st/h7/stm32h7.dtsi:455 */
			clock-frequency = < 0x186a0 >;   /* in zephyr/dts/arm/st/h7/stm32h7.dtsi:456 */
			#address-cells = < 0x1 >;        /* in zephyr/dts/arm/st/h7/stm32h7.dtsi:457 */
			#size-cells = < 0x0 >;           /* in zephyr/dts/arm/st/h7/stm32h7.dtsi:458 */
			reg = < 0x40005800 0x400 >;      /* in zephyr/dts/arm/st/h7/stm32h7.dtsi:459 */
			clocks = < &rcc 0xe8 0x400000 >; /* in zephyr/dts/arm/st/h7/stm32h7.dtsi:460 */
			interrupts = < 0x21 0x0 >,
			             < 0x22 0x0 >;       /* in zephyr/dts/arm/st/h7/stm32h7.dtsi:461 */
			interrupt-names = "event",
			                  "error";       /* in zephyr/dts/arm/st/h7/stm32h7.dtsi:462 */
			status = "disabled";             /* in zephyr/dts/arm/st/h7/stm32h7.dtsi:463 */
			phandle = < 0x25 >;              /* in zephyr/dts/arm/st/h7/stm32h7.dtsi:1382 */
		};

		/* node '/soc/i2c@40005c00' defined in zephyr/dts/arm/st/h7/stm32h7.dtsi:466 */
		i2c3: i2c@40005c00 {
			compatible = "st,stm32-i2c-v2";  /* in zephyr/dts/arm/st/h7/stm32h7.dtsi:467 */
			clock-frequency = < 0x186a0 >;   /* in zephyr/dts/arm/st/h7/stm32h7.dtsi:468 */
			#address-cells = < 0x1 >;        /* in zephyr/dts/arm/st/h7/stm32h7.dtsi:469 */
			#size-cells = < 0x0 >;           /* in zephyr/dts/arm/st/h7/stm32h7.dtsi:470 */
			reg = < 0x40005c00 0x400 >;      /* in zephyr/dts/arm/st/h7/stm32h7.dtsi:471 */
			clocks = < &rcc 0xe8 0x800000 >; /* in zephyr/dts/arm/st/h7/stm32h7.dtsi:472 */
			interrupts = < 0x48 0x0 >,
			             < 0x49 0x0 >;       /* in zephyr/dts/arm/st/h7/stm32h7.dtsi:473 */
			interrupt-names = "event",
			                  "error";       /* in zephyr/dts/arm/st/h7/stm32h7.dtsi:474 */
			status = "disabled";             /* in zephyr/dts/arm/st/h7/stm32h7.dtsi:475 */
			phandle = < 0x26 >;              /* in zephyr/dts/arm/st/h7/stm32h7.dtsi:1390 */
		};

		/* node '/soc/i2c@58001c00' defined in zephyr/dts/arm/st/h7/stm32h7.dtsi:478 */
		i2c4: i2c@58001c00 {
			compatible = "st,stm32-i2c-v2"; /* in zephyr/dts/arm/st/h7/stm32h7.dtsi:479 */
			clock-frequency = < 0x186a0 >;  /* in zephyr/dts/arm/st/h7/stm32h7.dtsi:480 */
			#address-cells = < 0x1 >;       /* in zephyr/dts/arm/st/h7/stm32h7.dtsi:481 */
			#size-cells = < 0x0 >;          /* in zephyr/dts/arm/st/h7/stm32h7.dtsi:482 */
			reg = < 0x58001c00 0x400 >;     /* in zephyr/dts/arm/st/h7/stm32h7.dtsi:483 */
			clocks = < &rcc 0xf4 0x80 >;    /* in zephyr/dts/arm/st/h7/stm32h7.dtsi:484 */
			interrupts = < 0x5f 0x0 >,
			             < 0x60 0x0 >;      /* in zephyr/dts/arm/st/h7/stm32h7.dtsi:485 */
			interrupt-names = "event",
			                  "error";      /* in zephyr/dts/arm/st/h7/stm32h7.dtsi:486 */
			status = "disabled";            /* in zephyr/dts/arm/st/h7/stm32h7.dtsi:487 */
			phandle = < 0x27 >;             /* in zephyr/dts/arm/st/h7/stm32h7.dtsi:1398 */
		};

		/* node '/soc/spi@40013000' defined in zephyr/dts/arm/st/h7/stm32h7.dtsi:490 */
		spi1: spi@40013000 {
			compatible = "st,stm32h7-spi",
			             "st,stm32-spi-fifo",
			             "st,stm32-spi";                                 /* in zephyr/dts/arm/st/h7/stm32h7.dtsi:491 */
			#address-cells = < 0x1 >;                                    /* in zephyr/dts/arm/st/h7/stm32h7.dtsi:492 */
			#size-cells = < 0x0 >;                                       /* in zephyr/dts/arm/st/h7/stm32h7.dtsi:493 */
			reg = < 0x40013000 0x400 >;                                  /* in zephyr/dts/arm/st/h7/stm32h7.dtsi:494 */
			clocks = < &rcc 0xf0 0x1000 >,
			         < &rcc 0x9 0x4c0050 >;                              /* in zephyr/dts/arm/st/h7/stm32h7.dtsi:495 */
			interrupts = < 0x23 0x0 >;                                   /* in zephyr/dts/arm/st/h7/stm32h7.dtsi:497 */
			st,spi-data-width = "full-4-to-32-bit";                      /* in zephyr/dts/arm/st/h7/stm32h7.dtsi:498 */
			fifo-size = < 0x10 >;                                        /* in zephyr/dts/arm/st/h7/stm32h7.dtsi:499 */
			fifo-max-transfer-size = < 0xffff >;                         /* in zephyr/dts/arm/st/h7/stm32h7.dtsi:500 */
			pinctrl-0 = < &spi1_sck_pb3 &spi1_miso_pb4 &spi1_mosi_pd7 >; /* in zephyr/boards/weact/mini_stm32h7b0/mini_stm32h7b0.dts:174 */
			cs-gpios = < &gpiod 0x6 0x1 >;                               /* in zephyr/boards/weact/mini_stm32h7b0/mini_stm32h7b0.dts:175 */
			pinctrl-names = "default";                                   /* in zephyr/boards/weact/mini_stm32h7b0/mini_stm32h7b0.dts:176 */
			status = "okay";                                             /* in zephyr/boards/weact/mini_stm32h7b0/mini_stm32h7b0.dts:177 */

			/* node '/soc/spi@40013000/spi-nor-flash@0' defined in zephyr/boards/weact/mini_stm32h7b0/mini_stm32h7b0.dts:179 */
			w25q64_spi: spi-nor-flash@0 {
				compatible = "jedec,spi-nor";      /* in zephyr/boards/weact/mini_stm32h7b0/mini_stm32h7b0.dts:180 */
				reg = < 0x0 >;                     /* in zephyr/boards/weact/mini_stm32h7b0/mini_stm32h7b0.dts:181 */
				spi-max-frequency = < 0x2625a00 >; /* in zephyr/boards/weact/mini_stm32h7b0/mini_stm32h7b0.dts:182 */
				size = < 0x4000000 >;              /* in zephyr/boards/weact/mini_stm32h7b0/mini_stm32h7b0.dts:183 */
				status = "okay";                   /* in zephyr/boards/weact/mini_stm32h7b0/mini_stm32h7b0.dts:184 */
				jedec-id = [ EF 40 17 ];           /* in zephyr/boards/weact/mini_stm32h7b0/mini_stm32h7b0.dts:185 */
				has-dpd;                           /* in zephyr/boards/weact/mini_stm32h7b0/mini_stm32h7b0.dts:186 */
				t-enter-dpd = < 0xdac >;           /* in zephyr/boards/weact/mini_stm32h7b0/mini_stm32h7b0.dts:187 */
				t-exit-dpd = < 0xdac >;            /* in zephyr/boards/weact/mini_stm32h7b0/mini_stm32h7b0.dts:188 */

				/* node '/soc/spi@40013000/spi-nor-flash@0/partitions' defined in zephyr/boards/weact/mini_stm32h7b0/mini_stm32h7b0.dts:190 */
				partitions {
					compatible = "fixed-partitions"; /* in zephyr/boards/weact/mini_stm32h7b0/mini_stm32h7b0.dts:191 */
					#address-cells = < 0x1 >;        /* in zephyr/boards/weact/mini_stm32h7b0/mini_stm32h7b0.dts:192 */
					#size-cells = < 0x1 >;           /* in zephyr/boards/weact/mini_stm32h7b0/mini_stm32h7b0.dts:193 */

					/* node '/soc/spi@40013000/spi-nor-flash@0/partitions/partition@0' defined in zephyr/boards/weact/mini_stm32h7b0/mini_stm32h7b0.dts:195 */
					storage_partition: partition@0 {
						label = "storage";       /* in zephyr/boards/weact/mini_stm32h7b0/mini_stm32h7b0.dts:196 */
						reg = < 0x0 0x4000000 >; /* in zephyr/boards/weact/mini_stm32h7b0/mini_stm32h7b0.dts:197 */
					};
				};
			};
		};

		/* node '/soc/spi@40003800' defined in zephyr/dts/arm/st/h7/stm32h7.dtsi:504 */
		spi2: spi@40003800 {
			compatible = "st,stm32h7-spi",
			             "st,stm32-spi-fifo",
			             "st,stm32-spi";            /* in zephyr/dts/arm/st/h7/stm32h7.dtsi:505 */
			#address-cells = < 0x1 >;               /* in zephyr/dts/arm/st/h7/stm32h7.dtsi:506 */
			#size-cells = < 0x0 >;                  /* in zephyr/dts/arm/st/h7/stm32h7.dtsi:507 */
			reg = < 0x40003800 0x400 >;             /* in zephyr/dts/arm/st/h7/stm32h7.dtsi:508 */
			clocks = < &rcc 0xe8 0x4000 >,
			         < &rcc 0x9 0x4c0050 >;         /* in zephyr/dts/arm/st/h7/stm32h7.dtsi:509 */
			interrupts = < 0x24 0x0 >;              /* in zephyr/dts/arm/st/h7/stm32h7.dtsi:511 */
			st,spi-data-width = "full-4-to-32-bit"; /* in zephyr/dts/arm/st/h7/stm32h7.dtsi:512 */
			fifo-size = < 0x10 >;                   /* in zephyr/dts/arm/st/h7/stm32h7.dtsi:513 */
			fifo-max-transfer-size = < 0xffff >;    /* in zephyr/dts/arm/st/h7/stm32h7.dtsi:514 */
			status = "disabled";                    /* in zephyr/dts/arm/st/h7/stm32h7.dtsi:515 */
		};

		/* node '/soc/spi@40003c00' defined in zephyr/dts/arm/st/h7/stm32h7.dtsi:518 */
		spi3: spi@40003c00 {
			compatible = "st,stm32h7-spi",
			             "st,stm32-spi-fifo",
			             "st,stm32-spi";            /* in zephyr/dts/arm/st/h7/stm32h7.dtsi:519 */
			#address-cells = < 0x1 >;               /* in zephyr/dts/arm/st/h7/stm32h7.dtsi:520 */
			#size-cells = < 0x0 >;                  /* in zephyr/dts/arm/st/h7/stm32h7.dtsi:521 */
			reg = < 0x40003c00 0x400 >;             /* in zephyr/dts/arm/st/h7/stm32h7.dtsi:522 */
			clocks = < &rcc 0xe8 0x8000 >,
			         < &rcc 0x9 0x4c0050 >;         /* in zephyr/dts/arm/st/h7/stm32h7.dtsi:523 */
			interrupts = < 0x33 0x0 >;              /* in zephyr/dts/arm/st/h7/stm32h7.dtsi:525 */
			st,spi-data-width = "full-4-to-32-bit"; /* in zephyr/dts/arm/st/h7/stm32h7.dtsi:526 */
			fifo-size = < 0x10 >;                   /* in zephyr/dts/arm/st/h7/stm32h7.dtsi:527 */
			fifo-max-transfer-size = < 0xffff >;    /* in zephyr/dts/arm/st/h7/stm32h7.dtsi:528 */
			status = "disabled";                    /* in zephyr/dts/arm/st/h7/stm32h7.dtsi:529 */
		};

		/* node '/soc/spi@40013400' defined in zephyr/dts/arm/st/h7/stm32h7.dtsi:532 */
		spi4: spi@40013400 {
			compatible = "st,stm32h7-spi",
			             "st,stm32-spi-fifo",
			             "st,stm32-spi";                    /* in zephyr/dts/arm/st/h7/stm32h7.dtsi:533 */
			#address-cells = < 0x1 >;                       /* in zephyr/dts/arm/st/h7/stm32h7.dtsi:534 */
			#size-cells = < 0x0 >;                          /* in zephyr/dts/arm/st/h7/stm32h7.dtsi:535 */
			reg = < 0x40013400 0x400 >;                     /* in zephyr/dts/arm/st/h7/stm32h7.dtsi:536 */
			clocks = < &rcc 0xf0 0x2000 >;                  /* in zephyr/dts/arm/st/h7/stm32h7.dtsi:537 */
			interrupts = < 0x54 0x0 >;                      /* in zephyr/dts/arm/st/h7/stm32h7.dtsi:538 */
			st,spi-data-width = "full-4-to-16-bit";         /* in zephyr/dts/arm/st/h7/stm32h7.dtsi:539 */
			fifo-size = < 0x8 >;                            /* in zephyr/dts/arm/st/h7/stm32h7.dtsi:541 */
			fifo-max-transfer-size = < 0xffff >;            /* in zephyr/dts/arm/st/h7/stm32h7.dtsi:542 */
			pinctrl-0 = < &spi4_sck_pe12 &spi4_mosi_pe14 >; /* in zephyr/boards/weact/mini_stm32h7b0/mini_stm32h7b0.dts:214 */
			cs-gpios = < &gpioe 0xb 0x1 >;                  /* in zephyr/boards/weact/mini_stm32h7b0/mini_stm32h7b0.dts:215 */
			pinctrl-names = "default";                      /* in zephyr/boards/weact/mini_stm32h7b0/mini_stm32h7b0.dts:216 */
			status = "okay";                                /* in zephyr/boards/weact/mini_stm32h7b0/mini_stm32h7b0.dts:217 */
			phandle = < 0x29 >;                             /* in zephyr/boards/weact/mini_stm32h7b0/mini_stm32h7b0.dts:44 */
		};

		/* node '/soc/spi@40015000' defined in zephyr/dts/arm/st/h7/stm32h7.dtsi:545 */
		spi5: spi@40015000 {
			compatible = "st,stm32h7-spi",
			             "st,stm32-spi-fifo",
			             "st,stm32-spi";            /* in zephyr/dts/arm/st/h7/stm32h7.dtsi:546 */
			#address-cells = < 0x1 >;               /* in zephyr/dts/arm/st/h7/stm32h7.dtsi:547 */
			#size-cells = < 0x0 >;                  /* in zephyr/dts/arm/st/h7/stm32h7.dtsi:548 */
			reg = < 0x40015000 0x400 >;             /* in zephyr/dts/arm/st/h7/stm32h7.dtsi:549 */
			clocks = < &rcc 0xf0 0x100000 >;        /* in zephyr/dts/arm/st/h7/stm32h7.dtsi:550 */
			interrupts = < 0x55 0x0 >;              /* in zephyr/dts/arm/st/h7/stm32h7.dtsi:551 */
			st,spi-data-width = "full-4-to-16-bit"; /* in zephyr/dts/arm/st/h7/stm32h7.dtsi:552 */
			fifo-size = < 0x8 >;                    /* in zephyr/dts/arm/st/h7/stm32h7.dtsi:553 */
			fifo-max-transfer-size = < 0xffff >;    /* in zephyr/dts/arm/st/h7/stm32h7.dtsi:554 */
			status = "disabled";                    /* in zephyr/dts/arm/st/h7/stm32h7.dtsi:555 */
		};

		/* node '/soc/spi@58001400' defined in zephyr/dts/arm/st/h7/stm32h7.dtsi:558 */
		spi6: spi@58001400 {
			compatible = "st,stm32h7-spi",
			             "st,stm32-spi-fifo",
			             "st,stm32-spi";            /* in zephyr/dts/arm/st/h7/stm32h7.dtsi:559 */
			#address-cells = < 0x1 >;               /* in zephyr/dts/arm/st/h7/stm32h7.dtsi:560 */
			#size-cells = < 0x0 >;                  /* in zephyr/dts/arm/st/h7/stm32h7.dtsi:561 */
			reg = < 0x58001400 0x400 >;             /* in zephyr/dts/arm/st/h7/stm32h7.dtsi:562 */
			clocks = < &rcc 0xf4 0x20 >;            /* in zephyr/dts/arm/st/h7/stm32h7.dtsi:563 */
			interrupts = < 0x56 0x0 >;              /* in zephyr/dts/arm/st/h7/stm32h7.dtsi:564 */
			st,spi-data-width = "full-4-to-16-bit"; /* in zephyr/dts/arm/st/h7/stm32h7.dtsi:565 */
			fifo-size = < 0x8 >;                    /* in zephyr/dts/arm/st/h7/stm32h7.dtsi:566 */
			fifo-max-transfer-size = < 0xffff >;    /* in zephyr/dts/arm/st/h7/stm32h7.dtsi:567 */
			status = "disabled";                    /* in zephyr/dts/arm/st/h7/stm32h7.dtsi:568 */
		};

		/* node '/soc/i2s@40013000' defined in zephyr/dts/arm/st/h7/stm32h7.dtsi:571 */
		i2s1: i2s@40013000 {
			compatible = "st,stm32h7-i2s",
			             "st,stm32-i2s";          /* in zephyr/dts/arm/st/h7/stm32h7.dtsi:572 */
			#address-cells = < 0x1 >;             /* in zephyr/dts/arm/st/h7/stm32h7.dtsi:573 */
			#size-cells = < 0x0 >;                /* in zephyr/dts/arm/st/h7/stm32h7.dtsi:574 */
			reg = < 0x40013000 0x400 >;           /* in zephyr/dts/arm/st/h7/stm32h7.dtsi:575 */
			clocks = < &rcc 0xf0 0x1000 >,
			         < &rcc 0x9 0x4c0050 >;       /* in zephyr/dts/arm/st/h7/stm32h7.dtsi:576 */
			dmas = < &dmamux1 0x0 0x26 0x20440 >,
			       < &dmamux1 0x1 0x25 0x20480 >; /* in zephyr/dts/arm/st/h7/stm32h7.dtsi:578 */
			dma-names = "tx",
			            "rx";                     /* in zephyr/dts/arm/st/h7/stm32h7.dtsi:580 */
			interrupts = < 0x23 0x0 >;            /* in zephyr/dts/arm/st/h7/stm32h7.dtsi:581 */
			status = "disabled";                  /* in zephyr/dts/arm/st/h7/stm32h7.dtsi:582 */
		};

		/* node '/soc/i2s@40003800' defined in zephyr/dts/arm/st/h7/stm32h7.dtsi:585 */
		i2s2: i2s@40003800 {
			compatible = "st,stm32h7-i2s",
			             "st,stm32-i2s";          /* in zephyr/dts/arm/st/h7/stm32h7.dtsi:586 */
			#address-cells = < 0x1 >;             /* in zephyr/dts/arm/st/h7/stm32h7.dtsi:587 */
			#size-cells = < 0x0 >;                /* in zephyr/dts/arm/st/h7/stm32h7.dtsi:588 */
			reg = < 0x40003800 0x400 >;           /* in zephyr/dts/arm/st/h7/stm32h7.dtsi:589 */
			clocks = < &rcc 0xe8 0x4000 >,
			         < &rcc 0x9 0x4c0050 >;       /* in zephyr/dts/arm/st/h7/stm32h7.dtsi:590 */
			dmas = < &dmamux1 0x0 0x28 0x20440 >,
			       < &dmamux1 0x1 0x27 0x20480 >; /* in zephyr/dts/arm/st/h7/stm32h7.dtsi:592 */
			dma-names = "tx",
			            "rx";                     /* in zephyr/dts/arm/st/h7/stm32h7.dtsi:594 */
			interrupts = < 0x24 0x0 >;            /* in zephyr/dts/arm/st/h7/stm32h7.dtsi:595 */
			status = "disabled";                  /* in zephyr/dts/arm/st/h7/stm32h7.dtsi:596 */
		};

		/* node '/soc/i2s@40003c00' defined in zephyr/dts/arm/st/h7/stm32h7.dtsi:599 */
		i2s3: i2s@40003c00 {
			compatible = "st,stm32h7-i2s",
			             "st,stm32-i2s";          /* in zephyr/dts/arm/st/h7/stm32h7.dtsi:600 */
			#address-cells = < 0x1 >;             /* in zephyr/dts/arm/st/h7/stm32h7.dtsi:601 */
			#size-cells = < 0x0 >;                /* in zephyr/dts/arm/st/h7/stm32h7.dtsi:602 */
			reg = < 0x40003c00 0x400 >;           /* in zephyr/dts/arm/st/h7/stm32h7.dtsi:603 */
			clocks = < &rcc 0xe8 0x8000 >,
			         < &rcc 0x9 0x4c0050 >;       /* in zephyr/dts/arm/st/h7/stm32h7.dtsi:604 */
			dmas = < &dmamux1 0x0 0x3e 0x20440 >,
			       < &dmamux1 0x1 0x3d 0x20480 >; /* in zephyr/dts/arm/st/h7/stm32h7.dtsi:606 */
			dma-names = "tx",
			            "rx";                     /* in zephyr/dts/arm/st/h7/stm32h7.dtsi:608 */
			interrupts = < 0x33 0x0 >;            /* in zephyr/dts/arm/st/h7/stm32h7.dtsi:609 */
			status = "disabled";                  /* in zephyr/dts/arm/st/h7/stm32h7.dtsi:610 */
		};

		/* node '/soc/can@4000a000' defined in zephyr/dts/arm/st/h7/stm32h7.dtsi:613 */
		fdcan1: can@4000a000 {
			compatible = "st,stm32h7-fdcan";                       /* in zephyr/dts/arm/st/h7/stm32h7.dtsi:614 */
			reg = < 0x4000a000 0x400 >,
			      < 0x4000ac00 0x350 >;                            /* in zephyr/dts/arm/st/h7/stm32h7.dtsi:615 */
			reg-names = "m_can",
			            "message_ram";                             /* in zephyr/dts/arm/st/h7/stm32h7.dtsi:616 */
			clocks = < &rcc 0xec 0x100 >;                          /* in zephyr/dts/arm/st/h7/stm32h7.dtsi:617 */
			interrupts = < 0x13 0x0 >,
			             < 0x15 0x0 >,
			             < 0x3f 0x0 >;                             /* in zephyr/dts/arm/st/h7/stm32h7.dtsi:618 */
			interrupt-names = "int0",
			                  "int1",
			                  "calib";                             /* in zephyr/dts/arm/st/h7/stm32h7.dtsi:619 */
			bosch,mram-cfg = < 0x0 0x1c 0x8 0x3 0x3 0x0 0x3 0x3 >; /* in zephyr/dts/arm/st/h7/stm32h7.dtsi:620 */
			status = "disabled";                                   /* in zephyr/dts/arm/st/h7/stm32h7.dtsi:621 */
		};

		/* node '/soc/can@4000a400' defined in zephyr/dts/arm/st/h7/stm32h7.dtsi:624 */
		fdcan2: can@4000a400 {
			compatible = "st,stm32h7-fdcan";                         /* in zephyr/dts/arm/st/h7/stm32h7.dtsi:625 */
			reg = < 0x4000a400 0x400 >,
			      < 0x4000ac00 0x6a0 >;                              /* in zephyr/dts/arm/st/h7/stm32h7.dtsi:626 */
			reg-names = "m_can",
			            "message_ram";                               /* in zephyr/dts/arm/st/h7/stm32h7.dtsi:627 */
			clocks = < &rcc 0xec 0x100 >;                            /* in zephyr/dts/arm/st/h7/stm32h7.dtsi:628 */
			interrupts = < 0x14 0x0 >,
			             < 0x16 0x0 >,
			             < 0x3f 0x0 >;                               /* in zephyr/dts/arm/st/h7/stm32h7.dtsi:629 */
			interrupt-names = "int0",
			                  "int1",
			                  "calib";                               /* in zephyr/dts/arm/st/h7/stm32h7.dtsi:630 */
			bosch,mram-cfg = < 0x350 0x1c 0x8 0x3 0x3 0x0 0x3 0x3 >; /* in zephyr/dts/arm/st/h7/stm32h7.dtsi:631 */
			status = "disabled";                                     /* in zephyr/dts/arm/st/h7/stm32h7.dtsi:632 */
		};

		/* node '/soc/timers@40010000' defined in zephyr/dts/arm/st/h7/stm32h7.dtsi:635 */
		timers1: timers@40010000 {
			compatible = "st,stm32-timers"; /* in zephyr/dts/arm/st/h7/stm32h7.dtsi:636 */
			reg = < 0x40010000 0x400 >;     /* in zephyr/dts/arm/st/h7/stm32h7.dtsi:637 */
			clocks = < &rcc 0xf0 0x1 >,
			         < &rcc 0x13 0xff >;    /* in zephyr/dts/arm/st/h7/stm32h7.dtsi:638 */
			resets = < &rctl 0x1300 >;      /* in zephyr/dts/arm/st/h7/stm32h7.dtsi:640 */
			interrupts = < 0x18 0x0 >,
			             < 0x19 0x0 >,
			             < 0x1a 0x0 >,
			             < 0x1b 0x0 >;      /* in zephyr/dts/arm/st/h7/stm32h7.dtsi:641 */
			interrupt-names = "brk",
			                  "up",
			                  "trgcom",
			                  "cc";         /* in zephyr/dts/arm/st/h7/stm32h7.dtsi:642 */
			st,prescaler = < 0x0 >;         /* in zephyr/dts/arm/st/h7/stm32h7.dtsi:643 */
			status = "disabled";            /* in zephyr/dts/arm/st/h7/stm32h7.dtsi:644 */

			/* node '/soc/timers@40010000/pwm' defined in zephyr/dts/arm/st/h7/stm32h7.dtsi:646 */
			pwm {
				compatible = "st,stm32-pwm"; /* in zephyr/dts/arm/st/h7/stm32h7.dtsi:647 */
				status = "disabled";         /* in zephyr/dts/arm/st/h7/stm32h7.dtsi:648 */
				#pwm-cells = < 0x3 >;        /* in zephyr/dts/arm/st/h7/stm32h7.dtsi:649 */
			};

			/* node '/soc/timers@40010000/counter' defined in zephyr/dts/arm/st/h7/stm32h7.dtsi:652 */
			counter {
				compatible = "st,stm32-counter"; /* in zephyr/dts/arm/st/h7/stm32h7.dtsi:653 */
				status = "disabled";             /* in zephyr/dts/arm/st/h7/stm32h7.dtsi:654 */
			};

			/* node '/soc/timers@40010000/qdec' defined in zephyr/dts/arm/st/h7/stm32h7.dtsi:657 */
			qdec {
				compatible = "st,stm32-qdec";    /* in zephyr/dts/arm/st/h7/stm32h7.dtsi:658 */
				st,input-filter-level = < 0x0 >; /* in zephyr/dts/arm/st/h7/stm32h7.dtsi:659 */
				status = "disabled";             /* in zephyr/dts/arm/st/h7/stm32h7.dtsi:660 */
			};
		};

		/* node '/soc/timers@40000000' defined in zephyr/dts/arm/st/h7/stm32h7.dtsi:664 */
		timers2: timers@40000000 {
			compatible = "st,stm32-timers"; /* in zephyr/dts/arm/st/h7/stm32h7.dtsi:665 */
			reg = < 0x40000000 0x400 >;     /* in zephyr/dts/arm/st/h7/stm32h7.dtsi:666 */
			clocks = < &rcc 0xe8 0x1 >,
			         < &rcc 0x12 0xff >;    /* in zephyr/dts/arm/st/h7/stm32h7.dtsi:667 */
			resets = < &rctl 0x1200 >;      /* in zephyr/dts/arm/st/h7/stm32h7.dtsi:669 */
			interrupts = < 0x1c 0x0 >;      /* in zephyr/dts/arm/st/h7/stm32h7.dtsi:670 */
			interrupt-names = "global";     /* in zephyr/dts/arm/st/h7/stm32h7.dtsi:671 */
			st,prescaler = < 0x0 >;         /* in zephyr/dts/arm/st/h7/stm32h7.dtsi:672 */
			status = "disabled";            /* in zephyr/dts/arm/st/h7/stm32h7.dtsi:673 */

			/* node '/soc/timers@40000000/pwm' defined in zephyr/dts/arm/st/h7/stm32h7.dtsi:675 */
			pwm {
				compatible = "st,stm32-pwm"; /* in zephyr/dts/arm/st/h7/stm32h7.dtsi:676 */
				status = "disabled";         /* in zephyr/dts/arm/st/h7/stm32h7.dtsi:677 */
				#pwm-cells = < 0x3 >;        /* in zephyr/dts/arm/st/h7/stm32h7.dtsi:678 */
			};

			/* node '/soc/timers@40000000/counter' defined in zephyr/dts/arm/st/h7/stm32h7.dtsi:681 */
			counter {
				compatible = "st,stm32-counter"; /* in zephyr/dts/arm/st/h7/stm32h7.dtsi:682 */
				status = "disabled";             /* in zephyr/dts/arm/st/h7/stm32h7.dtsi:683 */
			};

			/* node '/soc/timers@40000000/qdec' defined in zephyr/dts/arm/st/h7/stm32h7.dtsi:686 */
			qdec {
				compatible = "st,stm32-qdec";    /* in zephyr/dts/arm/st/h7/stm32h7.dtsi:687 */
				st,input-filter-level = < 0x0 >; /* in zephyr/dts/arm/st/h7/stm32h7.dtsi:688 */
				status = "disabled";             /* in zephyr/dts/arm/st/h7/stm32h7.dtsi:689 */
			};
		};

		/* node '/soc/timers@40000400' defined in zephyr/dts/arm/st/h7/stm32h7.dtsi:693 */
		timers3: timers@40000400 {
			compatible = "st,stm32-timers"; /* in zephyr/dts/arm/st/h7/stm32h7.dtsi:694 */
			reg = < 0x40000400 0x400 >;     /* in zephyr/dts/arm/st/h7/stm32h7.dtsi:695 */
			clocks = < &rcc 0xe8 0x2 >,
			         < &rcc 0x12 0xff >;    /* in zephyr/dts/arm/st/h7/stm32h7.dtsi:696 */
			resets = < &rctl 0x1201 >;      /* in zephyr/dts/arm/st/h7/stm32h7.dtsi:698 */
			interrupts = < 0x1d 0x0 >;      /* in zephyr/dts/arm/st/h7/stm32h7.dtsi:699 */
			interrupt-names = "global";     /* in zephyr/dts/arm/st/h7/stm32h7.dtsi:700 */
			st,prescaler = < 0x0 >;         /* in zephyr/dts/arm/st/h7/stm32h7.dtsi:701 */
			status = "disabled";            /* in zephyr/dts/arm/st/h7/stm32h7.dtsi:702 */

			/* node '/soc/timers@40000400/pwm' defined in zephyr/dts/arm/st/h7/stm32h7.dtsi:704 */
			pwm {
				compatible = "st,stm32-pwm"; /* in zephyr/dts/arm/st/h7/stm32h7.dtsi:705 */
				status = "disabled";         /* in zephyr/dts/arm/st/h7/stm32h7.dtsi:706 */
				#pwm-cells = < 0x3 >;        /* in zephyr/dts/arm/st/h7/stm32h7.dtsi:707 */
			};

			/* node '/soc/timers@40000400/counter' defined in zephyr/dts/arm/st/h7/stm32h7.dtsi:710 */
			counter {
				compatible = "st,stm32-counter"; /* in zephyr/dts/arm/st/h7/stm32h7.dtsi:711 */
				status = "disabled";             /* in zephyr/dts/arm/st/h7/stm32h7.dtsi:712 */
			};

			/* node '/soc/timers@40000400/qdec' defined in zephyr/dts/arm/st/h7/stm32h7.dtsi:715 */
			qdec {
				compatible = "st,stm32-qdec";    /* in zephyr/dts/arm/st/h7/stm32h7.dtsi:716 */
				st,input-filter-level = < 0x0 >; /* in zephyr/dts/arm/st/h7/stm32h7.dtsi:717 */
				status = "disabled";             /* in zephyr/dts/arm/st/h7/stm32h7.dtsi:718 */
			};
		};

		/* node '/soc/timers@40000800' defined in zephyr/dts/arm/st/h7/stm32h7.dtsi:722 */
		timers4: timers@40000800 {
			compatible = "st,stm32-timers"; /* in zephyr/dts/arm/st/h7/stm32h7.dtsi:723 */
			reg = < 0x40000800 0x400 >;     /* in zephyr/dts/arm/st/h7/stm32h7.dtsi:724 */
			clocks = < &rcc 0xe8 0x4 >,
			         < &rcc 0x12 0xff >;    /* in zephyr/dts/arm/st/h7/stm32h7.dtsi:725 */
			resets = < &rctl 0x1202 >;      /* in zephyr/dts/arm/st/h7/stm32h7.dtsi:727 */
			interrupts = < 0x1e 0x0 >;      /* in zephyr/dts/arm/st/h7/stm32h7.dtsi:728 */
			interrupt-names = "global";     /* in zephyr/dts/arm/st/h7/stm32h7.dtsi:729 */
			st,prescaler = < 0x0 >;         /* in zephyr/dts/arm/st/h7/stm32h7.dtsi:730 */
			status = "disabled";            /* in zephyr/dts/arm/st/h7/stm32h7.dtsi:731 */

			/* node '/soc/timers@40000800/pwm' defined in zephyr/dts/arm/st/h7/stm32h7.dtsi:733 */
			pwm {
				compatible = "st,stm32-pwm"; /* in zephyr/dts/arm/st/h7/stm32h7.dtsi:734 */
				status = "disabled";         /* in zephyr/dts/arm/st/h7/stm32h7.dtsi:735 */
				#pwm-cells = < 0x3 >;        /* in zephyr/dts/arm/st/h7/stm32h7.dtsi:736 */
			};

			/* node '/soc/timers@40000800/counter' defined in zephyr/dts/arm/st/h7/stm32h7.dtsi:739 */
			counter {
				compatible = "st,stm32-counter"; /* in zephyr/dts/arm/st/h7/stm32h7.dtsi:740 */
				status = "disabled";             /* in zephyr/dts/arm/st/h7/stm32h7.dtsi:741 */
			};

			/* node '/soc/timers@40000800/qdec' defined in zephyr/dts/arm/st/h7/stm32h7.dtsi:744 */
			qdec {
				compatible = "st,stm32-qdec";    /* in zephyr/dts/arm/st/h7/stm32h7.dtsi:745 */
				st,input-filter-level = < 0x0 >; /* in zephyr/dts/arm/st/h7/stm32h7.dtsi:746 */
				status = "disabled";             /* in zephyr/dts/arm/st/h7/stm32h7.dtsi:747 */
			};
		};

		/* node '/soc/timers@40000c00' defined in zephyr/dts/arm/st/h7/stm32h7.dtsi:751 */
		timers5: timers@40000c00 {
			compatible = "st,stm32-timers"; /* in zephyr/dts/arm/st/h7/stm32h7.dtsi:752 */
			reg = < 0x40000c00 0x400 >;     /* in zephyr/dts/arm/st/h7/stm32h7.dtsi:753 */
			clocks = < &rcc 0xe8 0x8 >,
			         < &rcc 0x12 0xff >;    /* in zephyr/dts/arm/st/h7/stm32h7.dtsi:754 */
			resets = < &rctl 0x1203 >;      /* in zephyr/dts/arm/st/h7/stm32h7.dtsi:756 */
			interrupts = < 0x32 0x0 >;      /* in zephyr/dts/arm/st/h7/stm32h7.dtsi:757 */
			interrupt-names = "global";     /* in zephyr/dts/arm/st/h7/stm32h7.dtsi:758 */
			st,prescaler = < 0x0 >;         /* in zephyr/dts/arm/st/h7/stm32h7.dtsi:759 */
			status = "disabled";            /* in zephyr/dts/arm/st/h7/stm32h7.dtsi:760 */

			/* node '/soc/timers@40000c00/pwm' defined in zephyr/dts/arm/st/h7/stm32h7.dtsi:762 */
			pwm {
				compatible = "st,stm32-pwm"; /* in zephyr/dts/arm/st/h7/stm32h7.dtsi:763 */
				status = "disabled";         /* in zephyr/dts/arm/st/h7/stm32h7.dtsi:764 */
				#pwm-cells = < 0x3 >;        /* in zephyr/dts/arm/st/h7/stm32h7.dtsi:765 */
			};

			/* node '/soc/timers@40000c00/counter' defined in zephyr/dts/arm/st/h7/stm32h7.dtsi:768 */
			counter {
				compatible = "st,stm32-counter"; /* in zephyr/dts/arm/st/h7/stm32h7.dtsi:769 */
				status = "disabled";             /* in zephyr/dts/arm/st/h7/stm32h7.dtsi:770 */
			};

			/* node '/soc/timers@40000c00/qdec' defined in zephyr/dts/arm/st/h7/stm32h7.dtsi:773 */
			qdec {
				compatible = "st,stm32-qdec";    /* in zephyr/dts/arm/st/h7/stm32h7.dtsi:774 */
				st,input-filter-level = < 0x0 >; /* in zephyr/dts/arm/st/h7/stm32h7.dtsi:775 */
				status = "disabled";             /* in zephyr/dts/arm/st/h7/stm32h7.dtsi:776 */
			};
		};

		/* node '/soc/timers@40001000' defined in zephyr/dts/arm/st/h7/stm32h7.dtsi:780 */
		timers6: timers@40001000 {
			compatible = "st,stm32-timers"; /* in zephyr/dts/arm/st/h7/stm32h7.dtsi:781 */
			reg = < 0x40001000 0x400 >;     /* in zephyr/dts/arm/st/h7/stm32h7.dtsi:782 */
			clocks = < &rcc 0xe8 0x10 >,
			         < &rcc 0x12 0xff >;    /* in zephyr/dts/arm/st/h7/stm32h7.dtsi:783 */
			resets = < &rctl 0x1204 >;      /* in zephyr/dts/arm/st/h7/stm32h7.dtsi:785 */
			interrupts = < 0x36 0x0 >;      /* in zephyr/dts/arm/st/h7/stm32h7.dtsi:786 */
			interrupt-names = "global";     /* in zephyr/dts/arm/st/h7/stm32h7.dtsi:787 */
			st,prescaler = < 0x0 >;         /* in zephyr/dts/arm/st/h7/stm32h7.dtsi:788 */
			status = "disabled";            /* in zephyr/dts/arm/st/h7/stm32h7.dtsi:789 */

			/* node '/soc/timers@40001000/counter' defined in zephyr/dts/arm/st/h7/stm32h7.dtsi:791 */
			counter {
				compatible = "st,stm32-counter"; /* in zephyr/dts/arm/st/h7/stm32h7.dtsi:792 */
				status = "disabled";             /* in zephyr/dts/arm/st/h7/stm32h7.dtsi:793 */
			};
		};

		/* node '/soc/timers@40001400' defined in zephyr/dts/arm/st/h7/stm32h7.dtsi:797 */
		timers7: timers@40001400 {
			compatible = "st,stm32-timers"; /* in zephyr/dts/arm/st/h7/stm32h7.dtsi:798 */
			reg = < 0x40001400 0x400 >;     /* in zephyr/dts/arm/st/h7/stm32h7.dtsi:799 */
			clocks = < &rcc 0xe8 0x20 >,
			         < &rcc 0x12 0xff >;    /* in zephyr/dts/arm/st/h7/stm32h7.dtsi:800 */
			resets = < &rctl 0x1205 >;      /* in zephyr/dts/arm/st/h7/stm32h7.dtsi:802 */
			interrupts = < 0x37 0x0 >;      /* in zephyr/dts/arm/st/h7/stm32h7.dtsi:803 */
			interrupt-names = "global";     /* in zephyr/dts/arm/st/h7/stm32h7.dtsi:804 */
			st,prescaler = < 0x0 >;         /* in zephyr/dts/arm/st/h7/stm32h7.dtsi:805 */
			status = "disabled";            /* in zephyr/dts/arm/st/h7/stm32h7.dtsi:806 */

			/* node '/soc/timers@40001400/counter' defined in zephyr/dts/arm/st/h7/stm32h7.dtsi:808 */
			counter {
				compatible = "st,stm32-counter"; /* in zephyr/dts/arm/st/h7/stm32h7.dtsi:809 */
				status = "disabled";             /* in zephyr/dts/arm/st/h7/stm32h7.dtsi:810 */
			};
		};

		/* node '/soc/timers@40010400' defined in zephyr/dts/arm/st/h7/stm32h7.dtsi:814 */
		timers8: timers@40010400 {
			compatible = "st,stm32-timers"; /* in zephyr/dts/arm/st/h7/stm32h7.dtsi:815 */
			reg = < 0x40010400 0x400 >;     /* in zephyr/dts/arm/st/h7/stm32h7.dtsi:816 */
			clocks = < &rcc 0xf0 0x2 >,
			         < &rcc 0x13 0xff >;    /* in zephyr/dts/arm/st/h7/stm32h7.dtsi:817 */
			resets = < &rctl 0x1301 >;      /* in zephyr/dts/arm/st/h7/stm32h7.dtsi:819 */
			interrupts = < 0x2b 0x0 >,
			             < 0x2c 0x0 >,
			             < 0x2d 0x0 >,
			             < 0x2e 0x0 >;      /* in zephyr/dts/arm/st/h7/stm32h7.dtsi:820 */
			interrupt-names = "brk",
			                  "up",
			                  "trgcom",
			                  "cc";         /* in zephyr/dts/arm/st/h7/stm32h7.dtsi:821 */
			st,prescaler = < 0x0 >;         /* in zephyr/dts/arm/st/h7/stm32h7.dtsi:822 */
			status = "disabled";            /* in zephyr/dts/arm/st/h7/stm32h7.dtsi:823 */

			/* node '/soc/timers@40010400/pwm' defined in zephyr/dts/arm/st/h7/stm32h7.dtsi:825 */
			pwm {
				compatible = "st,stm32-pwm"; /* in zephyr/dts/arm/st/h7/stm32h7.dtsi:826 */
				status = "disabled";         /* in zephyr/dts/arm/st/h7/stm32h7.dtsi:827 */
				#pwm-cells = < 0x3 >;        /* in zephyr/dts/arm/st/h7/stm32h7.dtsi:828 */
			};

			/* node '/soc/timers@40010400/counter' defined in zephyr/dts/arm/st/h7/stm32h7.dtsi:831 */
			counter {
				compatible = "st,stm32-counter"; /* in zephyr/dts/arm/st/h7/stm32h7.dtsi:832 */
				status = "disabled";             /* in zephyr/dts/arm/st/h7/stm32h7.dtsi:833 */
			};

			/* node '/soc/timers@40010400/qdec' defined in zephyr/dts/arm/st/h7/stm32h7.dtsi:836 */
			qdec {
				compatible = "st,stm32-qdec";    /* in zephyr/dts/arm/st/h7/stm32h7.dtsi:837 */
				st,input-filter-level = < 0x0 >; /* in zephyr/dts/arm/st/h7/stm32h7.dtsi:838 */
				status = "disabled";             /* in zephyr/dts/arm/st/h7/stm32h7.dtsi:839 */
			};
		};

		/* node '/soc/timers@40001800' defined in zephyr/dts/arm/st/h7/stm32h7.dtsi:843 */
		timers12: timers@40001800 {
			compatible = "st,stm32-timers"; /* in zephyr/dts/arm/st/h7/stm32h7.dtsi:844 */
			reg = < 0x40001800 0x400 >;     /* in zephyr/dts/arm/st/h7/stm32h7.dtsi:845 */
			clocks = < &rcc 0xe8 0x40 >,
			         < &rcc 0x12 0xff >;    /* in zephyr/dts/arm/st/h7/stm32h7.dtsi:846 */
			resets = < &rctl 0x1206 >;      /* in zephyr/dts/arm/st/h7/stm32h7.dtsi:848 */
			interrupts = < 0x2b 0x0 >;      /* in zephyr/dts/arm/st/h7/stm32h7.dtsi:849 */
			interrupt-names = "global";     /* in zephyr/dts/arm/st/h7/stm32h7.dtsi:850 */
			st,prescaler = < 0x0 >;         /* in zephyr/dts/arm/st/h7/stm32h7.dtsi:851 */
			status = "disabled";            /* in zephyr/dts/arm/st/h7/stm32h7.dtsi:852 */

			/* node '/soc/timers@40001800/pwm' defined in zephyr/dts/arm/st/h7/stm32h7.dtsi:854 */
			pwm {
				compatible = "st,stm32-pwm"; /* in zephyr/dts/arm/st/h7/stm32h7.dtsi:855 */
				status = "disabled";         /* in zephyr/dts/arm/st/h7/stm32h7.dtsi:856 */
				#pwm-cells = < 0x3 >;        /* in zephyr/dts/arm/st/h7/stm32h7.dtsi:857 */
			};

			/* node '/soc/timers@40001800/counter' defined in zephyr/dts/arm/st/h7/stm32h7.dtsi:860 */
			counter {
				compatible = "st,stm32-counter"; /* in zephyr/dts/arm/st/h7/stm32h7.dtsi:861 */
				status = "disabled";             /* in zephyr/dts/arm/st/h7/stm32h7.dtsi:862 */
			};
		};

		/* node '/soc/timers@40001c00' defined in zephyr/dts/arm/st/h7/stm32h7.dtsi:866 */
		timers13: timers@40001c00 {
			compatible = "st,stm32-timers"; /* in zephyr/dts/arm/st/h7/stm32h7.dtsi:867 */
			reg = < 0x40001c00 0x400 >;     /* in zephyr/dts/arm/st/h7/stm32h7.dtsi:868 */
			clocks = < &rcc 0xe8 0x80 >,
			         < &rcc 0x12 0xff >;    /* in zephyr/dts/arm/st/h7/stm32h7.dtsi:869 */
			resets = < &rctl 0x1207 >;      /* in zephyr/dts/arm/st/h7/stm32h7.dtsi:871 */
			interrupts = < 0x2c 0x0 >;      /* in zephyr/dts/arm/st/h7/stm32h7.dtsi:872 */
			interrupt-names = "global";     /* in zephyr/dts/arm/st/h7/stm32h7.dtsi:873 */
			st,prescaler = < 0x0 >;         /* in zephyr/dts/arm/st/h7/stm32h7.dtsi:874 */
			status = "disabled";            /* in zephyr/dts/arm/st/h7/stm32h7.dtsi:875 */

			/* node '/soc/timers@40001c00/pwm' defined in zephyr/dts/arm/st/h7/stm32h7.dtsi:877 */
			pwm {
				compatible = "st,stm32-pwm"; /* in zephyr/dts/arm/st/h7/stm32h7.dtsi:878 */
				status = "disabled";         /* in zephyr/dts/arm/st/h7/stm32h7.dtsi:879 */
				#pwm-cells = < 0x3 >;        /* in zephyr/dts/arm/st/h7/stm32h7.dtsi:880 */
			};

			/* node '/soc/timers@40001c00/counter' defined in zephyr/dts/arm/st/h7/stm32h7.dtsi:883 */
			counter {
				compatible = "st,stm32-counter"; /* in zephyr/dts/arm/st/h7/stm32h7.dtsi:884 */
				status = "disabled";             /* in zephyr/dts/arm/st/h7/stm32h7.dtsi:885 */
			};
		};

		/* node '/soc/timers@40002000' defined in zephyr/dts/arm/st/h7/stm32h7.dtsi:889 */
		timers14: timers@40002000 {
			compatible = "st,stm32-timers"; /* in zephyr/dts/arm/st/h7/stm32h7.dtsi:890 */
			reg = < 0x40002000 0x400 >;     /* in zephyr/dts/arm/st/h7/stm32h7.dtsi:891 */
			clocks = < &rcc 0xe8 0x100 >,
			         < &rcc 0x12 0xff >;    /* in zephyr/dts/arm/st/h7/stm32h7.dtsi:892 */
			resets = < &rctl 0x1208 >;      /* in zephyr/dts/arm/st/h7/stm32h7.dtsi:894 */
			interrupts = < 0x2d 0x0 >;      /* in zephyr/dts/arm/st/h7/stm32h7.dtsi:895 */
			interrupt-names = "global";     /* in zephyr/dts/arm/st/h7/stm32h7.dtsi:896 */
			st,prescaler = < 0x0 >;         /* in zephyr/dts/arm/st/h7/stm32h7.dtsi:897 */
			status = "disabled";            /* in zephyr/dts/arm/st/h7/stm32h7.dtsi:898 */

			/* node '/soc/timers@40002000/pwm' defined in zephyr/dts/arm/st/h7/stm32h7.dtsi:900 */
			pwm {
				compatible = "st,stm32-pwm"; /* in zephyr/dts/arm/st/h7/stm32h7.dtsi:901 */
				status = "disabled";         /* in zephyr/dts/arm/st/h7/stm32h7.dtsi:902 */
				#pwm-cells = < 0x3 >;        /* in zephyr/dts/arm/st/h7/stm32h7.dtsi:903 */
			};

			/* node '/soc/timers@40002000/counter' defined in zephyr/dts/arm/st/h7/stm32h7.dtsi:906 */
			counter {
				compatible = "st,stm32-counter"; /* in zephyr/dts/arm/st/h7/stm32h7.dtsi:907 */
				status = "disabled";             /* in zephyr/dts/arm/st/h7/stm32h7.dtsi:908 */
			};
		};

		/* node '/soc/timers@40014000' defined in zephyr/dts/arm/st/h7/stm32h7.dtsi:912 */
		timers15: timers@40014000 {
			compatible = "st,stm32-timers"; /* in zephyr/dts/arm/st/h7/stm32h7.dtsi:913 */
			reg = < 0x40014000 0x400 >;     /* in zephyr/dts/arm/st/h7/stm32h7.dtsi:914 */
			clocks = < &rcc 0xf0 0x10000 >,
			         < &rcc 0x13 0xff >;    /* in zephyr/dts/arm/st/h7/stm32h7.dtsi:915 */
			resets = < &rctl 0x1310 >;      /* in zephyr/dts/arm/st/h7/stm32h7.dtsi:917 */
			interrupts = < 0x74 0x0 >;      /* in zephyr/dts/arm/st/h7/stm32h7.dtsi:918 */
			interrupt-names = "global";     /* in zephyr/dts/arm/st/h7/stm32h7.dtsi:919 */
			st,prescaler = < 0x0 >;         /* in zephyr/dts/arm/st/h7/stm32h7.dtsi:920 */
			status = "disabled";            /* in zephyr/dts/arm/st/h7/stm32h7.dtsi:921 */

			/* node '/soc/timers@40014000/pwm' defined in zephyr/dts/arm/st/h7/stm32h7.dtsi:923 */
			pwm {
				compatible = "st,stm32-pwm"; /* in zephyr/dts/arm/st/h7/stm32h7.dtsi:924 */
				status = "disabled";         /* in zephyr/dts/arm/st/h7/stm32h7.dtsi:925 */
				#pwm-cells = < 0x3 >;        /* in zephyr/dts/arm/st/h7/stm32h7.dtsi:926 */
			};

			/* node '/soc/timers@40014000/counter' defined in zephyr/dts/arm/st/h7/stm32h7.dtsi:929 */
			counter {
				compatible = "st,stm32-counter"; /* in zephyr/dts/arm/st/h7/stm32h7.dtsi:930 */
				status = "disabled";             /* in zephyr/dts/arm/st/h7/stm32h7.dtsi:931 */
			};
		};

		/* node '/soc/timers@40014400' defined in zephyr/dts/arm/st/h7/stm32h7.dtsi:935 */
		timers16: timers@40014400 {
			compatible = "st,stm32-timers"; /* in zephyr/dts/arm/st/h7/stm32h7.dtsi:936 */
			reg = < 0x40014400 0x400 >;     /* in zephyr/dts/arm/st/h7/stm32h7.dtsi:937 */
			clocks = < &rcc 0xf0 0x20000 >,
			         < &rcc 0x13 0xff >;    /* in zephyr/dts/arm/st/h7/stm32h7.dtsi:938 */
			resets = < &rctl 0x1311 >;      /* in zephyr/dts/arm/st/h7/stm32h7.dtsi:940 */
			interrupts = < 0x75 0x0 >;      /* in zephyr/dts/arm/st/h7/stm32h7.dtsi:941 */
			interrupt-names = "global";     /* in zephyr/dts/arm/st/h7/stm32h7.dtsi:942 */
			st,prescaler = < 0x0 >;         /* in zephyr/dts/arm/st/h7/stm32h7.dtsi:943 */
			status = "disabled";            /* in zephyr/dts/arm/st/h7/stm32h7.dtsi:944 */

			/* node '/soc/timers@40014400/pwm' defined in zephyr/dts/arm/st/h7/stm32h7.dtsi:946 */
			pwm {
				compatible = "st,stm32-pwm"; /* in zephyr/dts/arm/st/h7/stm32h7.dtsi:947 */
				status = "disabled";         /* in zephyr/dts/arm/st/h7/stm32h7.dtsi:948 */
				#pwm-cells = < 0x3 >;        /* in zephyr/dts/arm/st/h7/stm32h7.dtsi:949 */
			};

			/* node '/soc/timers@40014400/counter' defined in zephyr/dts/arm/st/h7/stm32h7.dtsi:952 */
			counter {
				compatible = "st,stm32-counter"; /* in zephyr/dts/arm/st/h7/stm32h7.dtsi:953 */
				status = "disabled";             /* in zephyr/dts/arm/st/h7/stm32h7.dtsi:954 */
			};
		};

		/* node '/soc/timers@40014800' defined in zephyr/dts/arm/st/h7/stm32h7.dtsi:958 */
		timers17: timers@40014800 {
			compatible = "st,stm32-timers"; /* in zephyr/dts/arm/st/h7/stm32h7.dtsi:959 */
			reg = < 0x40014800 0x400 >;     /* in zephyr/dts/arm/st/h7/stm32h7.dtsi:960 */
			clocks = < &rcc 0xf0 0x40000 >,
			         < &rcc 0x13 0xff >;    /* in zephyr/dts/arm/st/h7/stm32h7.dtsi:961 */
			resets = < &rctl 0x1312 >;      /* in zephyr/dts/arm/st/h7/stm32h7.dtsi:963 */
			interrupts = < 0x76 0x0 >;      /* in zephyr/dts/arm/st/h7/stm32h7.dtsi:964 */
			interrupt-names = "global";     /* in zephyr/dts/arm/st/h7/stm32h7.dtsi:965 */
			st,prescaler = < 0x0 >;         /* in zephyr/dts/arm/st/h7/stm32h7.dtsi:966 */
			status = "disabled";            /* in zephyr/dts/arm/st/h7/stm32h7.dtsi:967 */

			/* node '/soc/timers@40014800/pwm' defined in zephyr/dts/arm/st/h7/stm32h7.dtsi:969 */
			pwm {
				compatible = "st,stm32-pwm"; /* in zephyr/dts/arm/st/h7/stm32h7.dtsi:970 */
				status = "disabled";         /* in zephyr/dts/arm/st/h7/stm32h7.dtsi:971 */
				#pwm-cells = < 0x3 >;        /* in zephyr/dts/arm/st/h7/stm32h7.dtsi:972 */
			};

			/* node '/soc/timers@40014800/counter' defined in zephyr/dts/arm/st/h7/stm32h7.dtsi:975 */
			counter {
				compatible = "st,stm32-counter"; /* in zephyr/dts/arm/st/h7/stm32h7.dtsi:976 */
				status = "disabled";             /* in zephyr/dts/arm/st/h7/stm32h7.dtsi:977 */
			};
		};

		/* node '/soc/timers@40002400' defined in zephyr/dts/arm/st/h7/stm32h7.dtsi:981 */
		lptim1: timers@40002400 {
			compatible = "st,stm32-lptim"; /* in zephyr/dts/arm/st/h7/stm32h7.dtsi:982 */
			clocks = < &rcc 0xe8 0x200 >;  /* in zephyr/dts/arm/st/h7/stm32h7.dtsi:983 */
			resets = < &rctl 0x1209 >;     /* in zephyr/dts/arm/st/h7/stm32h7.dtsi:984 */
			#address-cells = < 0x1 >;      /* in zephyr/dts/arm/st/h7/stm32h7.dtsi:985 */
			#size-cells = < 0x0 >;         /* in zephyr/dts/arm/st/h7/stm32h7.dtsi:986 */
			reg = < 0x40002400 0x400 >;    /* in zephyr/dts/arm/st/h7/stm32h7.dtsi:987 */
			interrupts = < 0x5d 0x0 >;     /* in zephyr/dts/arm/st/h7/stm32h7.dtsi:988 */
			interrupt-names = "wakeup";    /* in zephyr/dts/arm/st/h7/stm32h7.dtsi:989 */
			status = "disabled";           /* in zephyr/dts/arm/st/h7/stm32h7.dtsi:990 */
		};

		/* node '/soc/dfsdm@40017000' defined in zephyr/dts/arm/st/h7/stm32h7.dtsi:993 */
		dfsdm: dfsdm@40017000 {
			compatible = "st,stm32-dfsdm";     /* in zephyr/dts/arm/st/h7/stm32h7.dtsi:994 */
			reg = < 0x40017000 0x400 >;        /* in zephyr/dts/arm/st/h7/stm32h7.dtsi:995 */
			clocks = < &rcc 0xf0 0x10000000 >,
			         < &rcc 0xb 0x1400050 >;   /* in zephyr/dts/arm/st/h7/stm32h7.dtsi:996 */
			clock-names = "pclk",
			              "aclk";              /* in zephyr/dts/arm/st/h7/stm32h7.dtsi:998 */
			resets = < &rctl 0x131c >;         /* in zephyr/dts/arm/st/h7/stm32h7.dtsi:999 */
			#address-cells = < 0x1 >;          /* in zephyr/dts/arm/st/h7/stm32h7.dtsi:1000 */
			#size-cells = < 0x0 >;             /* in zephyr/dts/arm/st/h7/stm32h7.dtsi:1001 */
			status = "disabled";               /* in zephyr/dts/arm/st/h7/stm32h7.dtsi:1002 */

			/* node '/soc/dfsdm@40017000/filter@0' defined in zephyr/dts/arm/st/h7/stm32h7.dtsi:1004 */
			pdm0: filter@0 {
				compatible = "st,stm32-dfsdm-dmic"; /* in zephyr/dts/arm/st/h7/stm32h7.dtsi:1005 */
				reg = < 0x0 >;                      /* in zephyr/dts/arm/st/h7/stm32h7.dtsi:1006 */
				interrupts = < 0x6e 0x0 >;          /* in zephyr/dts/arm/st/h7/stm32h7.dtsi:1007 */
				filter-order = < 0x5 >;             /* in zephyr/dts/arm/st/h7/stm32h7.dtsi:1008 */
				#address-cells = < 0x1 >;           /* in zephyr/dts/arm/st/h7/stm32h7.dtsi:1009 */
				#size-cells = < 0x0 >;              /* in zephyr/dts/arm/st/h7/stm32h7.dtsi:1010 */
				status = "disabled";                /* in zephyr/dts/arm/st/h7/stm32h7.dtsi:1011 */
			};

			/* node '/soc/dfsdm@40017000/filter@1' defined in zephyr/dts/arm/st/h7/stm32h7.dtsi:1014 */
			pdm1: filter@1 {
				compatible = "st,stm32-dfsdm-dmic"; /* in zephyr/dts/arm/st/h7/stm32h7.dtsi:1015 */
				reg = < 0x1 >;                      /* in zephyr/dts/arm/st/h7/stm32h7.dtsi:1016 */
				interrupts = < 0x6f 0x0 >;          /* in zephyr/dts/arm/st/h7/stm32h7.dtsi:1017 */
				filter-order = < 0x5 >;             /* in zephyr/dts/arm/st/h7/stm32h7.dtsi:1018 */
				#address-cells = < 0x1 >;           /* in zephyr/dts/arm/st/h7/stm32h7.dtsi:1019 */
				#size-cells = < 0x0 >;              /* in zephyr/dts/arm/st/h7/stm32h7.dtsi:1020 */
				status = "disabled";                /* in zephyr/dts/arm/st/h7/stm32h7.dtsi:1021 */
			};

			/* node '/soc/dfsdm@40017000/filter@2' defined in zephyr/dts/arm/st/h7/stm32h7.dtsi:1024 */
			pdm2: filter@2 {
				compatible = "st,stm32-dfsdm-dmic"; /* in zephyr/dts/arm/st/h7/stm32h7.dtsi:1025 */
				reg = < 0x2 >;                      /* in zephyr/dts/arm/st/h7/stm32h7.dtsi:1026 */
				interrupts = < 0x70 0x0 >;          /* in zephyr/dts/arm/st/h7/stm32h7.dtsi:1027 */
				filter-order = < 0x5 >;             /* in zephyr/dts/arm/st/h7/stm32h7.dtsi:1028 */
				#address-cells = < 0x1 >;           /* in zephyr/dts/arm/st/h7/stm32h7.dtsi:1029 */
				#size-cells = < 0x0 >;              /* in zephyr/dts/arm/st/h7/stm32h7.dtsi:1030 */
				status = "disabled";                /* in zephyr/dts/arm/st/h7/stm32h7.dtsi:1031 */
			};

			/* node '/soc/dfsdm@40017000/filter@3' defined in zephyr/dts/arm/st/h7/stm32h7.dtsi:1034 */
			pdm3: filter@3 {
				compatible = "st,stm32-dfsdm-dmic"; /* in zephyr/dts/arm/st/h7/stm32h7.dtsi:1035 */
				reg = < 0x3 >;                      /* in zephyr/dts/arm/st/h7/stm32h7.dtsi:1036 */
				interrupts = < 0x71 0x0 >;          /* in zephyr/dts/arm/st/h7/stm32h7.dtsi:1037 */
				filter-order = < 0x5 >;             /* in zephyr/dts/arm/st/h7/stm32h7.dtsi:1038 */
				#address-cells = < 0x1 >;           /* in zephyr/dts/arm/st/h7/stm32h7.dtsi:1039 */
				#size-cells = < 0x0 >;              /* in zephyr/dts/arm/st/h7/stm32h7.dtsi:1040 */
				status = "disabled";                /* in zephyr/dts/arm/st/h7/stm32h7.dtsi:1041 */
			};

			/* node '/soc/dfsdm@40017000/filter@4' defined in zephyr/dts/arm/st/h7/stm32h7a3.dtsi:231 */
			pdm4: filter@4 {
				compatible = "st,stm32-dfsdm-dmic"; /* in zephyr/dts/arm/st/h7/stm32h7a3.dtsi:232 */
				reg = < 0x4 >;                      /* in zephyr/dts/arm/st/h7/stm32h7a3.dtsi:233 */
				interrupts = < 0x40 0x0 >;          /* in zephyr/dts/arm/st/h7/stm32h7a3.dtsi:234 */
				#address-cells = < 0x1 >;           /* in zephyr/dts/arm/st/h7/stm32h7a3.dtsi:235 */
				#size-cells = < 0x0 >;              /* in zephyr/dts/arm/st/h7/stm32h7a3.dtsi:236 */
				status = "disabled";                /* in zephyr/dts/arm/st/h7/stm32h7a3.dtsi:237 */
			};

			/* node '/soc/dfsdm@40017000/filter@5' defined in zephyr/dts/arm/st/h7/stm32h7a3.dtsi:240 */
			pdm5: filter@5 {
				compatible = "st,stm32-dfsdm-dmic"; /* in zephyr/dts/arm/st/h7/stm32h7a3.dtsi:241 */
				reg = < 0x5 >;                      /* in zephyr/dts/arm/st/h7/stm32h7a3.dtsi:242 */
				interrupts = < 0x41 0x0 >;          /* in zephyr/dts/arm/st/h7/stm32h7a3.dtsi:243 */
				#address-cells = < 0x1 >;           /* in zephyr/dts/arm/st/h7/stm32h7a3.dtsi:244 */
				#size-cells = < 0x0 >;              /* in zephyr/dts/arm/st/h7/stm32h7a3.dtsi:245 */
				status = "disabled";                /* in zephyr/dts/arm/st/h7/stm32h7a3.dtsi:246 */
			};

			/* node '/soc/dfsdm@40017000/filter@6' defined in zephyr/dts/arm/st/h7/stm32h7a3.dtsi:249 */
			pdm6: filter@6 {
				compatible = "st,stm32-dfsdm-dmic"; /* in zephyr/dts/arm/st/h7/stm32h7a3.dtsi:250 */
				reg = < 0x6 >;                      /* in zephyr/dts/arm/st/h7/stm32h7a3.dtsi:251 */
				interrupts = < 0x42 0x0 >;          /* in zephyr/dts/arm/st/h7/stm32h7a3.dtsi:252 */
				#address-cells = < 0x1 >;           /* in zephyr/dts/arm/st/h7/stm32h7a3.dtsi:253 */
				#size-cells = < 0x0 >;              /* in zephyr/dts/arm/st/h7/stm32h7a3.dtsi:254 */
				status = "disabled";                /* in zephyr/dts/arm/st/h7/stm32h7a3.dtsi:255 */
			};

			/* node '/soc/dfsdm@40017000/filter@7' defined in zephyr/dts/arm/st/h7/stm32h7a3.dtsi:258 */
			pdm7: filter@7 {
				compatible = "st,stm32-dfsdm-dmic"; /* in zephyr/dts/arm/st/h7/stm32h7a3.dtsi:259 */
				reg = < 0x7 >;                      /* in zephyr/dts/arm/st/h7/stm32h7a3.dtsi:260 */
				interrupts = < 0x43 0x0 >;          /* in zephyr/dts/arm/st/h7/stm32h7a3.dtsi:261 */
				#address-cells = < 0x1 >;           /* in zephyr/dts/arm/st/h7/stm32h7a3.dtsi:262 */
				#size-cells = < 0x0 >;              /* in zephyr/dts/arm/st/h7/stm32h7a3.dtsi:263 */
				status = "disabled";                /* in zephyr/dts/arm/st/h7/stm32h7a3.dtsi:264 */
			};
		};

		/* node '/soc/adc@40022000' defined in zephyr/dts/arm/st/h7/stm32h7.dtsi:1045 */
		adc1: adc@40022000 {
			compatible = "st,stm32-adc";                                 /* in zephyr/dts/arm/st/h7/stm32h7.dtsi:1046 */
			reg = < 0x40022000 0x400 >;                                  /* in zephyr/dts/arm/st/h7/stm32h7.dtsi:1047 */
			clocks = < &rcc 0xd8 0x20 >;                                 /* in zephyr/dts/arm/st/h7/stm32h7.dtsi:1048 */
			clock-names = "adcx";                                        /* in zephyr/dts/arm/st/h7/stm32h7.dtsi:1049 */
			interrupts = < 0x12 0x0 >;                                   /* in zephyr/dts/arm/st/h7/stm32h7.dtsi:1050 */
			#io-channel-cells = < 0x1 >;                                 /* in zephyr/dts/arm/st/h7/stm32h7.dtsi:1051 */
			st,adc-resolutions = < 0x10 0xe 0xc 0xa 0x8 >;               /* in zephyr/dts/arm/st/h7/stm32h7.dtsi:1052 */
			sampling-times = < 0x2 0x3 0x9 0x11 0x21 0x41 0x184 0x32b >; /* in zephyr/dts/arm/st/h7/stm32h7.dtsi:1053 */
			st,adc-sequencer = "programmable";                           /* in zephyr/dts/arm/st/h7/stm32h7.dtsi:1054 */
			st,adc-oversampler = "extended";                             /* in zephyr/dts/arm/st/h7/stm32h7.dtsi:1055 */
			st,adc-internal-regulator = "startup-hw-status";             /* in zephyr/dts/arm/st/h7/stm32h7.dtsi:1056 */
			st,adc-has-deep-powerdown;                                   /* in zephyr/dts/arm/st/h7/stm32h7.dtsi:1057 */
			st,adc-has-channel-preselection;                             /* in zephyr/dts/arm/st/h7/stm32h7.dtsi:1058 */
			st,adc-has-differential-support;                             /* in zephyr/dts/arm/st/h7/stm32h7.dtsi:1059 */
			st,adc-has-injected-support;                                 /* in zephyr/dts/arm/st/h7/stm32h7.dtsi:1060 */
			status = "disabled";                                         /* in zephyr/dts/arm/st/h7/stm32h7.dtsi:1061 */
		};

		/* node '/soc/adc@40022100' defined in zephyr/dts/arm/st/h7/stm32h7.dtsi:1064 */
		adc2: adc@40022100 {
			compatible = "st,stm32-adc";                                 /* in zephyr/dts/arm/st/h7/stm32h7.dtsi:1065 */
			reg = < 0x40022100 0x400 >;                                  /* in zephyr/dts/arm/st/h7/stm32h7.dtsi:1066 */
			clocks = < &rcc 0xd8 0x20 >;                                 /* in zephyr/dts/arm/st/h7/stm32h7.dtsi:1067 */
			clock-names = "adcx";                                        /* in zephyr/dts/arm/st/h7/stm32h7.dtsi:1068 */
			interrupts = < 0x12 0x0 >;                                   /* in zephyr/dts/arm/st/h7/stm32h7.dtsi:1069 */
			#io-channel-cells = < 0x1 >;                                 /* in zephyr/dts/arm/st/h7/stm32h7.dtsi:1070 */
			st,adc-resolutions = < 0x10 0xe 0xc 0xa 0x8 >;               /* in zephyr/dts/arm/st/h7/stm32h7.dtsi:1071 */
			sampling-times = < 0x2 0x3 0x9 0x11 0x21 0x41 0x184 0x32b >; /* in zephyr/dts/arm/st/h7/stm32h7.dtsi:1072 */
			st,adc-sequencer = "programmable";                           /* in zephyr/dts/arm/st/h7/stm32h7.dtsi:1073 */
			st,adc-oversampler = "extended";                             /* in zephyr/dts/arm/st/h7/stm32h7.dtsi:1074 */
			st,adc-internal-regulator = "startup-hw-status";             /* in zephyr/dts/arm/st/h7/stm32h7.dtsi:1075 */
			st,adc-has-deep-powerdown;                                   /* in zephyr/dts/arm/st/h7/stm32h7.dtsi:1076 */
			st,adc-has-channel-preselection;                             /* in zephyr/dts/arm/st/h7/stm32h7.dtsi:1077 */
			st,adc-has-differential-support;                             /* in zephyr/dts/arm/st/h7/stm32h7.dtsi:1078 */
			st,adc-has-injected-support;                                 /* in zephyr/dts/arm/st/h7/stm32h7.dtsi:1079 */
			status = "disabled";                                         /* in zephyr/dts/arm/st/h7/stm32h7.dtsi:1080 */
			phandle = < 0x22 >;                                          /* in zephyr/dts/arm/st/h7/stm32h7a3.dtsi:217 */
		};

		/* node '/soc/adc@40022300' defined in zephyr/dts/arm/st/h7/stm32h7.dtsi:1084 */
		adc1_2: adc@40022300 {
			compatible = "st,stm32-adc";                                 /* in zephyr/dts/arm/st/h7/stm32h7.dtsi:1085 */
			reg = < 0x40022300 0x400 >;                                  /* in zephyr/dts/arm/st/h7/stm32h7.dtsi:1086 */
			clocks = < &rcc 0xd8 0x20 >;                                 /* in zephyr/dts/arm/st/h7/stm32h7.dtsi:1087 */
			clock-names = "adcx";                                        /* in zephyr/dts/arm/st/h7/stm32h7.dtsi:1088 */
			interrupts = < 0x12 0x0 >;                                   /* in zephyr/dts/arm/st/h7/stm32h7.dtsi:1089 */
			#io-channel-cells = < 0x1 >;                                 /* in zephyr/dts/arm/st/h7/stm32h7.dtsi:1090 */
			st,adc-resolutions = < 0x10 0xe 0xc 0xa 0x8 >;               /* in zephyr/dts/arm/st/h7/stm32h7.dtsi:1091 */
			sampling-times = < 0x2 0x3 0x9 0x11 0x21 0x41 0x184 0x32b >; /* in zephyr/dts/arm/st/h7/stm32h7.dtsi:1092 */
			st,adc-sequencer = "programmable";                           /* in zephyr/dts/arm/st/h7/stm32h7.dtsi:1093 */
			st,adc-oversampler = "extended";                             /* in zephyr/dts/arm/st/h7/stm32h7.dtsi:1094 */
			st,adc-internal-regulator = "startup-hw-status";             /* in zephyr/dts/arm/st/h7/stm32h7.dtsi:1095 */
			st,adc-has-deep-powerdown;                                   /* in zephyr/dts/arm/st/h7/stm32h7.dtsi:1096 */
			st,adc-has-channel-preselection;                             /* in zephyr/dts/arm/st/h7/stm32h7.dtsi:1097 */
			st,adc-has-differential-support;                             /* in zephyr/dts/arm/st/h7/stm32h7.dtsi:1098 */
			st,adc-has-injected-support;                                 /* in zephyr/dts/arm/st/h7/stm32h7.dtsi:1099 */
			status = "disabled";                                         /* in zephyr/dts/arm/st/h7/stm32h7.dtsi:1100 */
		};

		/* node '/soc/dac@40007400' defined in zephyr/dts/arm/st/h7/stm32h7.dtsi:1122 */
		dac1: dac@40007400 {
			compatible = "st,stm32-dac";       /* in zephyr/dts/arm/st/h7/stm32h7.dtsi:1123 */
			reg = < 0x40007400 0x400 >;        /* in zephyr/dts/arm/st/h7/stm32h7.dtsi:1124 */
			clocks = < &rcc 0xe8 0x20000000 >; /* in zephyr/dts/arm/st/h7/stm32h7.dtsi:1125 */
			status = "disabled";               /* in zephyr/dts/arm/st/h7/stm32h7.dtsi:1126 */
			#io-channel-cells = < 0x1 >;       /* in zephyr/dts/arm/st/h7/stm32h7.dtsi:1127 */
		};

		/* node '/soc/dma@40020000' defined in zephyr/dts/arm/st/h7/stm32h7.dtsi:1130 */
		dma1: dma@40020000 {
			compatible = "st,stm32-dma-v1"; /* in zephyr/dts/arm/st/h7/stm32h7.dtsi:1131 */
			#dma-cells = < 0x4 >;           /* in zephyr/dts/arm/st/h7/stm32h7.dtsi:1132 */
			reg = < 0x40020000 0x400 >;     /* in zephyr/dts/arm/st/h7/stm32h7.dtsi:1133 */
			interrupts = < 0xb 0x0 >,
			             < 0xc 0x0 >,
			             < 0xd 0x0 >,
			             < 0xe 0x0 >,
			             < 0xf 0x0 >,
			             < 0x10 0x0 >,
			             < 0x11 0x0 >,
			             < 0x2f 0x0 >;      /* in zephyr/dts/arm/st/h7/stm32h7.dtsi:1134 */
			clocks = < &rcc 0xd8 0x1 >;     /* in zephyr/dts/arm/st/h7/stm32h7.dtsi:1136 */
			st,mem2mem;                     /* in zephyr/dts/arm/st/h7/stm32h7.dtsi:1137 */
			dma-offset = < 0x0 >;           /* in zephyr/dts/arm/st/h7/stm32h7.dtsi:1138 */
			dma-requests = < 0x8 >;         /* in zephyr/dts/arm/st/h7/stm32h7.dtsi:1139 */
			status = "disabled";            /* in zephyr/dts/arm/st/h7/stm32h7.dtsi:1140 */
			phandle = < 0x1a >;             /* in zephyr/dts/arm/st/h7/stm32h7.dtsi:1286 */
		};

		/* node '/soc/dma@40020400' defined in zephyr/dts/arm/st/h7/stm32h7.dtsi:1143 */
		dma2: dma@40020400 {
			compatible = "st,stm32-dma-v1"; /* in zephyr/dts/arm/st/h7/stm32h7.dtsi:1144 */
			#dma-cells = < 0x4 >;           /* in zephyr/dts/arm/st/h7/stm32h7.dtsi:1145 */
			reg = < 0x40020400 0x400 >;     /* in zephyr/dts/arm/st/h7/stm32h7.dtsi:1146 */
			interrupts = < 0x38 0x0 >,
			             < 0x39 0x0 >,
			             < 0x3a 0x0 >,
			             < 0x3b 0x0 >,
			             < 0x3c 0x0 >,
			             < 0x44 0x0 >,
			             < 0x45 0x0 >,
			             < 0x46 0x0 >;      /* in zephyr/dts/arm/st/h7/stm32h7.dtsi:1147 */
			clocks = < &rcc 0xd8 0x2 >;     /* in zephyr/dts/arm/st/h7/stm32h7.dtsi:1149 */
			st,mem2mem;                     /* in zephyr/dts/arm/st/h7/stm32h7.dtsi:1150 */
			dma-offset = < 0x8 >;           /* in zephyr/dts/arm/st/h7/stm32h7.dtsi:1151 */
			dma-requests = < 0x8 >;         /* in zephyr/dts/arm/st/h7/stm32h7.dtsi:1152 */
			status = "disabled";            /* in zephyr/dts/arm/st/h7/stm32h7.dtsi:1153 */
		};

		/* node '/soc/bdma@58025400' defined in zephyr/dts/arm/st/h7/stm32h7.dtsi:1156 */
		bdma1: bdma@58025400 {
			compatible = "st,stm32-bdma";    /* in zephyr/dts/arm/st/h7/stm32h7.dtsi:1157 */
			#dma-cells = < 0x4 >;            /* in zephyr/dts/arm/st/h7/stm32h7.dtsi:1158 */
			reg = < 0x58025400 0x400 >;      /* in zephyr/dts/arm/st/h7/stm32h7.dtsi:1159 */
			interrupts = < 0x81 0x0 >,
			             < 0x82 0x0 >,
			             < 0x83 0x0 >,
			             < 0x84 0x0 >,
			             < 0x85 0x0 >,
			             < 0x86 0x0 >,
			             < 0x87 0x0 >,
			             < 0x88 0x0 >;       /* in zephyr/dts/arm/st/h7/stm32h7.dtsi:1160 */
			clocks = < &rcc 0xe0 0x200000 >; /* in zephyr/dts/arm/st/h7/stm32h7.dtsi:1162 */
			st,mem2mem;                      /* in zephyr/dts/arm/st/h7/stm32h7.dtsi:1163 */
			dma-offset = < 0x0 >;            /* in zephyr/dts/arm/st/h7/stm32h7.dtsi:1164 */
			dma-requests = < 0x8 >;          /* in zephyr/dts/arm/st/h7/stm32h7.dtsi:1165 */
			status = "disabled";             /* in zephyr/dts/arm/st/h7/stm32h7.dtsi:1166 */
		};

		/* node '/soc/dmamux@40020800' defined in zephyr/dts/arm/st/h7/stm32h7.dtsi:1169 */
		dmamux1: dmamux@40020800 {
			compatible = "st,stm32-dmamux"; /* in zephyr/dts/arm/st/h7/stm32h7.dtsi:1170 */
			#dma-cells = < 0x3 >;           /* in zephyr/dts/arm/st/h7/stm32h7.dtsi:1171 */
			reg = < 0x40020800 0x400 >;     /* in zephyr/dts/arm/st/h7/stm32h7.dtsi:1172 */
			interrupts = < 0x66 0x0 >;      /* in zephyr/dts/arm/st/h7/stm32h7.dtsi:1173 */
			clocks = < &rcc 0xd8 0x1 >;     /* in zephyr/dts/arm/st/h7/stm32h7.dtsi:1175 */
			dma-channels = < 0x10 >;        /* in zephyr/dts/arm/st/h7/stm32h7.dtsi:1176 */
			dma-generators = < 0x8 >;       /* in zephyr/dts/arm/st/h7/stm32h7.dtsi:1177 */
			status = "disabled";            /* in zephyr/dts/arm/st/h7/stm32h7.dtsi:1178 */
			dma-requests = < 0x6b >;        /* in zephyr/dts/arm/st/h7/stm32h7a3.dtsi:67 */
			phandle = < 0xc >;              /* in zephyr/dts/arm/st/h7/stm32h7.dtsi:578 */
		};

		/* node '/soc/dmamux@58025800' defined in zephyr/dts/arm/st/h7/stm32h7.dtsi:1185 */
		dmamux2: dmamux@58025800 {
			compatible = "st,stm32-dmamux";  /* in zephyr/dts/arm/st/h7/stm32h7.dtsi:1186 */
			#dma-cells = < 0x3 >;            /* in zephyr/dts/arm/st/h7/stm32h7.dtsi:1187 */
			reg = < 0x58025800 0x400 >;      /* in zephyr/dts/arm/st/h7/stm32h7.dtsi:1188 */
			interrupts = < 0x80 0x0 >;       /* in zephyr/dts/arm/st/h7/stm32h7.dtsi:1189 */
			clocks = < &rcc 0xe0 0x200000 >; /* in zephyr/dts/arm/st/h7/stm32h7.dtsi:1191 */
			dma-channels = < 0x8 >;          /* in zephyr/dts/arm/st/h7/stm32h7.dtsi:1192 */
			dma-generators = < 0x8 >;        /* in zephyr/dts/arm/st/h7/stm32h7.dtsi:1193 */
			status = "disabled";             /* in zephyr/dts/arm/st/h7/stm32h7.dtsi:1194 */
			dma-requests = < 0x6b >;         /* in zephyr/dts/arm/st/h7/stm32h7a3.dtsi:71 */
			phandle = < 0x1e >;              /* in zephyr/dts/arm/st/h7/stm32h7a3.dtsi:129 */
		};

		/* node '/soc/rng@48021800' defined in zephyr/dts/arm/st/h7/stm32h7.dtsi:1201 */
		rng: rng@48021800 {
			compatible = "st,stm32-rng";        /* in zephyr/dts/arm/st/h7/stm32h7.dtsi:1202 */
			reg = < 0x48021800 0x400 >;         /* in zephyr/dts/arm/st/h7/stm32h7.dtsi:1203 */
			clocks = < &rcc 0xdc 0x40 >;        /* in zephyr/dts/arm/st/h7/stm32h7.dtsi:1204 */
			interrupts = < 0x50 0x0 >;          /* in zephyr/dts/arm/st/h7/stm32h7.dtsi:1205 */
			nist-config = < 0xf00d00 >;         /* in zephyr/dts/arm/st/h7/stm32h7a3.dtsi:137 */
			health-test-magic = < 0x17590abc >; /* in zephyr/dts/arm/st/h7/stm32h7a3.dtsi:138 */
			health-test-config = < 0x72ac >;    /* in zephyr/dts/arm/st/h7/stm32h7a3.dtsi:139 */
			status = "okay";                    /* in zephyr/boards/weact/mini_stm32h7b0/mini_stm32h7b0.dts:221 */
		};

		/* node '/soc/sdmmc@52007000' defined in zephyr/dts/arm/st/h7/stm32h7.dtsi:1209 */
		sdmmc1: sdmmc@52007000 {
			compatible = "st,stm32-sdmmc";                                                                                 /* in zephyr/dts/arm/st/h7/stm32h7.dtsi:1210 */
			reg = < 0x52007000 0x400 >;                                                                                    /* in zephyr/dts/arm/st/h7/stm32h7.dtsi:1211 */
			clocks = < &rcc 0xd4 0x10000 >,
			         < &rcc 0x9 0x10004c >;                                                                                /* in zephyr/dts/arm/st/h7/stm32h7.dtsi:1212 */
			resets = < &rctl 0xf90 >;                                                                                      /* in zephyr/dts/arm/st/h7/stm32h7.dtsi:1214 */
			interrupts = < 0x31 0x0 >;                                                                                     /* in zephyr/dts/arm/st/h7/stm32h7.dtsi:1215 */
			pinctrl-0 = < &sdmmc1_d0_pc8 &sdmmc1_d1_pc9 &sdmmc1_d2_pc10 &sdmmc1_d3_pc11 &sdmmc1_ck_pc12 &sdmmc1_cmd_pd2 >; /* in zephyr/boards/weact/mini_stm32h7b0/mini_stm32h7b0.dts:127 */
			pinctrl-names = "default";                                                                                     /* in zephyr/boards/weact/mini_stm32h7b0/mini_stm32h7b0.dts:130 */
			cd-gpios = < &gpiod 0x4 0x10 >;                                                                                /* in zephyr/boards/weact/mini_stm32h7b0/mini_stm32h7b0.dts:131 */
			disk-name = "SD";                                                                                              /* in zephyr/boards/weact/mini_stm32h7b0/mini_stm32h7b0.dts:132 */
			status = "okay";                                                                                               /* in zephyr/boards/weact/mini_stm32h7b0/mini_stm32h7b0.dts:133 */
		};

		/* node '/soc/sdmmc@48022400' defined in zephyr/dts/arm/st/h7/stm32h7.dtsi:1219 */
		sdmmc2: sdmmc@48022400 {
			compatible = "st,stm32-sdmmc";  /* in zephyr/dts/arm/st/h7/stm32h7.dtsi:1220 */
			reg = < 0x48022400 0x400 >;     /* in zephyr/dts/arm/st/h7/stm32h7.dtsi:1221 */
			clocks = < &rcc 0xdc 0x200 >,
			         < &rcc 0x9 0x10004c >; /* in zephyr/dts/arm/st/h7/stm32h7.dtsi:1222 */
			resets = < &rctl 0x1089 >;      /* in zephyr/dts/arm/st/h7/stm32h7.dtsi:1224 */
			interrupts = < 0x7c 0x0 >;      /* in zephyr/dts/arm/st/h7/stm32h7.dtsi:1225 */
			status = "disabled";            /* in zephyr/dts/arm/st/h7/stm32h7.dtsi:1226 */
		};

		/* node '/soc/ethernet@40028000' defined in zephyr/dts/arm/st/h7/stm32h7.dtsi:1229 */
		mac: ethernet@40028000 {
			compatible = "st,stm32h7-ethernet",
			             "st,stm32-ethernet";   /* in zephyr/dts/arm/st/h7/stm32h7.dtsi:1230 */
			reg = < 0x40028000 0x8000 >;        /* in zephyr/dts/arm/st/h7/stm32h7.dtsi:1231 */
			clock-names = "stm-eth",
			              "mac-clk-tx",
			              "mac-clk-rx";         /* in zephyr/dts/arm/st/h7/stm32h7.dtsi:1232 */
			clocks = < &rcc 0xd8 0x8000 >,
			         < &rcc 0xd8 0x10000 >,
			         < &rcc 0xd8 0x20000 >;     /* in zephyr/dts/arm/st/h7/stm32h7.dtsi:1233 */
			interrupts = < 0x3d 0x0 >;          /* in zephyr/dts/arm/st/h7/stm32h7.dtsi:1236 */
			status = "disabled";                /* in zephyr/dts/arm/st/h7/stm32h7.dtsi:1238 */
			memory-regions = < &sram3 >;        /* in zephyr/dts/arm/st/h7/stm32h7a3.dtsi:269 */

			/* node '/soc/ethernet@40028000/mdio' defined in zephyr/dts/arm/st/h7/stm32h7.dtsi:1240 */
			mdio: mdio {
				compatible = "st,stm32-mdio",
				             "snps,dwmac-mdio"; /* in zephyr/dts/arm/st/h7/stm32h7.dtsi:1241 */
				#address-cells = < 0x1 >;       /* in zephyr/dts/arm/st/h7/stm32h7.dtsi:1242 */
				#size-cells = < 0x0 >;          /* in zephyr/dts/arm/st/h7/stm32h7.dtsi:1243 */
				status = "disabled";            /* in zephyr/dts/arm/st/h7/stm32h7.dtsi:1244 */
			};
		};

		/* node '/soc/memory-controller@52004000' defined in zephyr/dts/arm/st/h7/stm32h7.dtsi:1248 */
		fmc: memory-controller@52004000 {
			compatible = "st,stm32h7-fmc"; /* in zephyr/dts/arm/st/h7/stm32h7.dtsi:1249 */
			reg = < 0x52004000 0x400 >;    /* in zephyr/dts/arm/st/h7/stm32h7.dtsi:1250 */
			clocks = < &rcc 0xd4 0x1000 >; /* in zephyr/dts/arm/st/h7/stm32h7.dtsi:1251 */
			status = "disabled";           /* in zephyr/dts/arm/st/h7/stm32h7.dtsi:1252 */

			/* node '/soc/memory-controller@52004000/sdram' defined in zephyr/dts/arm/st/h7/stm32h7.dtsi:1254 */
			sdram: sdram {
				compatible = "st,stm32-fmc-sdram"; /* in zephyr/dts/arm/st/h7/stm32h7.dtsi:1255 */
				#address-cells = < 0x1 >;          /* in zephyr/dts/arm/st/h7/stm32h7.dtsi:1256 */
				#size-cells = < 0x0 >;             /* in zephyr/dts/arm/st/h7/stm32h7.dtsi:1257 */
				status = "disabled";               /* in zephyr/dts/arm/st/h7/stm32h7.dtsi:1258 */
			};
		};

		/* node '/soc/memory@38800000' defined in zephyr/dts/arm/st/h7/stm32h7.dtsi:1262 */
		backup_sram: memory@38800000 {
			compatible = "zephyr,memory-region",
			             "st,stm32-backup-sram";  /* in zephyr/dts/arm/st/h7/stm32h7.dtsi:1263 */
			reg = < 0x38800000 0x1000 >;          /* in zephyr/dts/arm/st/h7/stm32h7.dtsi:1264 */
			clocks = < &rcc 0xe0 0x10000000 >;    /* in zephyr/dts/arm/st/h7/stm32h7.dtsi:1265 */
			zephyr,memory-region = "BACKUP_SRAM"; /* in zephyr/dts/arm/st/h7/stm32h7.dtsi:1266 */
			status = "okay";                      /* in zephyr/boards/weact/mini_stm32h7b0/mini_stm32h7b0.dts:225 */
		};

		/* node '/soc/spi@52005000' defined in zephyr/dts/arm/st/h7/stm32h7.dtsi:1270 */
		quadspi: octospi1: spi@52005000 {
			compatible = "st,stm32-ospi";                                                                       /* in zephyr/dts/arm/st/h7/stm32h7a3.dtsi:99 */
			reg = < 0x52005000 0x1000 >,
			      < 0x90000000 0x10000000 >;                                                                    /* in zephyr/dts/arm/st/h7/stm32h7a3.dtsi:100 */
			interrupts = < 0x5c 0x0 >;                                                                          /* in zephyr/dts/arm/st/h7/stm32h7a3.dtsi:101 */
			clock-names = "ospix",
			              "ospi-ker";                                                                           /* in zephyr/dts/arm/st/h7/stm32h7a3.dtsi:102 */
			clocks = < &rcc 0xd4 0x4000 >,
			         < &rcc 0x9 0x124004c >;                                                                    /* in zephyr/dts/arm/st/h7/stm32h7a3.dtsi:103 */
			#address-cells = < 0x1 >;                                                                           /* in zephyr/dts/arm/st/h7/stm32h7a3.dtsi:105 */
			#size-cells = < 0x0 >;                                                                              /* in zephyr/dts/arm/st/h7/stm32h7a3.dtsi:106 */
			pinctrl-names = "default";                                                                          /* in zephyr/boards/weact/mini_stm32h7b0/mini_stm32h7b0.dts:145 */
			pinctrl-0 = < &octospim_p1_clk_pb2 &octospim_p1_ncs_pb6 &octospim_p1_io0_pd11 &octospim_p1_io1_pd12
			              &octospim_p1_io2_pe2 &octospim_p1_io3_pd13 >;                                         /* in zephyr/boards/weact/mini_stm32h7b0/mini_stm32h7b0.dts:146 */
			status = "okay";                                                                                    /* in zephyr/boards/weact/mini_stm32h7b0/mini_stm32h7b0.dts:149 */

			/* node '/soc/spi@52005000/ospi-nor-flash@0' defined in zephyr/boards/weact/mini_stm32h7b0/mini_stm32h7b0.dts:151 */
			w25q64_qspi: ospi-nor-flash@0 {
				compatible = "st,stm32-ospi-nor";   /* in zephyr/boards/weact/mini_stm32h7b0/mini_stm32h7b0.dts:152 */
				reg = < 0x0 >;                      /* in zephyr/boards/weact/mini_stm32h7b0/mini_stm32h7b0.dts:153 */
				size = < 0x4000000 >;               /* in zephyr/boards/weact/mini_stm32h7b0/mini_stm32h7b0.dts:154 */
				ospi-max-frequency = < 0x2625a00 >; /* in zephyr/boards/weact/mini_stm32h7b0/mini_stm32h7b0.dts:155 */
				status = "okay";                    /* in zephyr/boards/weact/mini_stm32h7b0/mini_stm32h7b0.dts:156 */
				spi-bus-width = < 0x4 >;            /* in zephyr/boards/weact/mini_stm32h7b0/mini_stm32h7b0.dts:157 */
				data-rate = < 0x1 >;                /* in zephyr/boards/weact/mini_stm32h7b0/mini_stm32h7b0.dts:158 */
				writeoc = "PP_1_1_4";               /* in zephyr/boards/weact/mini_stm32h7b0/mini_stm32h7b0.dts:159 */

				/* node '/soc/spi@52005000/ospi-nor-flash@0/partitions' defined in zephyr/boards/weact/mini_stm32h7b0/mini_stm32h7b0.dts:161 */
				partitions {
					compatible = "fixed-partitions"; /* in zephyr/boards/weact/mini_stm32h7b0/mini_stm32h7b0.dts:162 */
					#address-cells = < 0x1 >;        /* in zephyr/boards/weact/mini_stm32h7b0/mini_stm32h7b0.dts:163 */
					#size-cells = < 0x1 >;           /* in zephyr/boards/weact/mini_stm32h7b0/mini_stm32h7b0.dts:164 */

					/* node '/soc/spi@52005000/ospi-nor-flash@0/partitions/partition@0' defined in zephyr/boards/weact/mini_stm32h7b0/mini_stm32h7b0.dts:166 */
					slot0_partition: partition@0 {
						reg = < 0x0 0x800000 >; /* in zephyr/boards/weact/mini_stm32h7b0/mini_stm32h7b0.dts:167 */
					};
				};
			};
		};

		/* node '/soc/dcmi@48020000' defined in zephyr/dts/arm/st/h7/stm32h7.dtsi:1280 */
		dcmi: dcmi@48020000 {
			compatible = "st,stm32-dcmi";          /* in zephyr/dts/arm/st/h7/stm32h7.dtsi:1281 */
			reg = < 0x48020000 0x400 >;            /* in zephyr/dts/arm/st/h7/stm32h7.dtsi:1282 */
			interrupts = < 0x4e 0x0 >;             /* in zephyr/dts/arm/st/h7/stm32h7.dtsi:1283 */
			interrupt-names = "dcmi";              /* in zephyr/dts/arm/st/h7/stm32h7.dtsi:1284 */
			clocks = < &rcc 0xdc 0x1 >;            /* in zephyr/dts/arm/st/h7/stm32h7.dtsi:1285 */
			dmas = < &dma1 0x1 0x4b 0x24480 0x0 >; /* in zephyr/dts/arm/st/h7/stm32h7.dtsi:1286 */
			status = "disabled";                   /* in zephyr/dts/arm/st/h7/stm32h7.dtsi:1290 */
		};

		/* node '/soc/sai1@40015804' defined in zephyr/dts/arm/st/h7/stm32h7.dtsi:1293 */
		sai1_a: sai1@40015804 {
			compatible = "st,stm32-sai";           /* in zephyr/dts/arm/st/h7/stm32h7.dtsi:1294 */
			#address-cells = < 0x1 >;              /* in zephyr/dts/arm/st/h7/stm32h7.dtsi:1295 */
			#size-cells = < 0x0 >;                 /* in zephyr/dts/arm/st/h7/stm32h7.dtsi:1296 */
			reg = < 0x40015804 0x20 >;             /* in zephyr/dts/arm/st/h7/stm32h7.dtsi:1297 */
			clocks = < &rcc 0xf0 0x400000 >,
			         < &rcc 0xb 0x1400050 >;       /* in zephyr/dts/arm/st/h7/stm32h7.dtsi:1298 */
			dmas = < &dma1 0x2 0x57 0x22800 0x0 >; /* in zephyr/dts/arm/st/h7/stm32h7.dtsi:1300 */
			status = "disabled";                   /* in zephyr/dts/arm/st/h7/stm32h7.dtsi:1302 */
		};

		/* node '/soc/sai1@40015824' defined in zephyr/dts/arm/st/h7/stm32h7.dtsi:1305 */
		sai1_b: sai1@40015824 {
			compatible = "st,stm32-sai";           /* in zephyr/dts/arm/st/h7/stm32h7.dtsi:1306 */
			#address-cells = < 0x1 >;              /* in zephyr/dts/arm/st/h7/stm32h7.dtsi:1307 */
			#size-cells = < 0x0 >;                 /* in zephyr/dts/arm/st/h7/stm32h7.dtsi:1308 */
			reg = < 0x40015824 0x20 >;             /* in zephyr/dts/arm/st/h7/stm32h7.dtsi:1309 */
			clocks = < &rcc 0xf0 0x400000 >,
			         < &rcc 0xb 0x1400050 >;       /* in zephyr/dts/arm/st/h7/stm32h7.dtsi:1310 */
			dmas = < &dma1 0x3 0x58 0x22800 0x0 >; /* in zephyr/dts/arm/st/h7/stm32h7.dtsi:1312 */
			status = "disabled";                   /* in zephyr/dts/arm/st/h7/stm32h7.dtsi:1314 */
		};

		/* node '/soc/comparator@5800380c' defined in zephyr/dts/arm/st/h7/stm32h7.dtsi:1317 */
		comp1_ch1: comparator@5800380c {
			compatible = "st,stm32h7-comp",
			             "st,stm32-comp";   /* in zephyr/dts/arm/st/h7/stm32h7.dtsi:1318 */
			reg = < 0x5800380c 0x200 >;     /* in zephyr/dts/arm/st/h7/stm32h7.dtsi:1319 */
			interrupts = < 0x89 0x0 >;      /* in zephyr/dts/arm/st/h7/stm32h7.dtsi:1320 */
			st,exti-line = < 0x14 >;        /* in zephyr/dts/arm/st/h7/stm32h7.dtsi:1321 */
			clocks = < &rcc 0xf4 0x4000 >;  /* in zephyr/dts/arm/st/h7/stm32h7.dtsi:1322 */
			status = "disabled";            /* in zephyr/dts/arm/st/h7/stm32h7.dtsi:1323 */
		};

		/* node '/soc/comparator@58003810' defined in zephyr/dts/arm/st/h7/stm32h7.dtsi:1326 */
		comp1_ch2: comparator@58003810 {
			compatible = "st,stm32h7-comp",
			             "st,stm32-comp";   /* in zephyr/dts/arm/st/h7/stm32h7.dtsi:1327 */
			reg = < 0x58003810 0x200 >;     /* in zephyr/dts/arm/st/h7/stm32h7.dtsi:1328 */
			interrupts = < 0x89 0x0 >;      /* in zephyr/dts/arm/st/h7/stm32h7.dtsi:1329 */
			st,exti-line = < 0x14 >;        /* in zephyr/dts/arm/st/h7/stm32h7.dtsi:1330 */
			clocks = < &rcc 0xf4 0x4000 >;  /* in zephyr/dts/arm/st/h7/stm32h7.dtsi:1331 */
			status = "disabled";            /* in zephyr/dts/arm/st/h7/stm32h7.dtsi:1332 */
		};

		/* node '/soc/usb@40040000' defined in zephyr/dts/arm/st/h7/stm32h7a3.dtsi:74 */
		usbotg_hs: zephyr_udc0: usb@40040000 {
			compatible = "st,stm32-otghs";                           /* in zephyr/dts/arm/st/h7/stm32h7a3.dtsi:75 */
			reg = < 0x40040000 0x40000 >;                            /* in zephyr/dts/arm/st/h7/stm32h7a3.dtsi:76 */
			interrupts = < 0x4d 0x0 >,
			             < 0x4a 0x0 >,
			             < 0x4b 0x0 >;                               /* in zephyr/dts/arm/st/h7/stm32h7a3.dtsi:77 */
			interrupt-names = "otghs",
			                  "ep1_out",
			                  "ep1_in";                              /* in zephyr/dts/arm/st/h7/stm32h7a3.dtsi:78 */
			num-bidir-endpoints = < 0x9 >;                           /* in zephyr/dts/arm/st/h7/stm32h7a3.dtsi:79 */
			ram-size = < 0x1000 >;                                   /* in zephyr/dts/arm/st/h7/stm32h7a3.dtsi:80 */
			maximum-speed = "full-speed";                            /* in zephyr/dts/arm/st/h7/stm32h7a3.dtsi:81 */
			clocks = < &rcc 0xd8 0x2000000 >,
			         < &rcc 0x5 0x3340054 >;                         /* in zephyr/dts/arm/st/h7/stm32h7a3.dtsi:82 */
			phys = < &otghs_fs_phy >;                                /* in zephyr/dts/arm/st/h7/stm32h7a3.dtsi:84 */
			pinctrl-0 = < &usb_otg_hs_dm_pa11 &usb_otg_hs_dp_pa12 >; /* in zephyr/boards/weact/mini_stm32h7b0/mini_stm32h7b0.dts:137 */
			pinctrl-names = "default";                               /* in zephyr/boards/weact/mini_stm32h7b0/mini_stm32h7b0.dts:138 */
			status = "okay";                                         /* in zephyr/boards/weact/mini_stm32h7b0/mini_stm32h7b0.dts:139 */

			/* node '/soc/usb@40040000/board_cdc_acm_uart' defined in zephyr/boards/common/usb/cdc_acm_serial.dtsi:18 */
			board_cdc_acm_uart: board_cdc_acm_uart {
				compatible = "zephyr,cdc-acm-uart"; /* in zephyr/boards/common/usb/cdc_acm_serial.dtsi:19 */
			};
		};

		/* node '/soc/display-controller@50001000' defined in zephyr/dts/arm/st/h7/stm32h7a3.dtsi:88 */
		ltdc: display-controller@50001000 {
			compatible = "st,stm32-ltdc"; /* in zephyr/dts/arm/st/h7/stm32h7a3.dtsi:89 */
			reg = < 0x50001000 0x200 >;   /* in zephyr/dts/arm/st/h7/stm32h7a3.dtsi:90 */
			interrupts = < 0x58 0x0 >,
			             < 0x59 0x0 >;    /* in zephyr/dts/arm/st/h7/stm32h7a3.dtsi:91 */
			interrupt-names = "ltdc",
			                  "ltdc_er";  /* in zephyr/dts/arm/st/h7/stm32h7a3.dtsi:92 */
			clocks = < &rcc 0xe4 0x8 >;   /* in zephyr/dts/arm/st/h7/stm32h7a3.dtsi:93 */
			resets = < &rctl 0x1183 >;    /* in zephyr/dts/arm/st/h7/stm32h7a3.dtsi:94 */
			status = "disabled";          /* in zephyr/dts/arm/st/h7/stm32h7a3.dtsi:95 */
		};

		/* node '/soc/spi@5200a000' defined in zephyr/dts/arm/st/h7/stm32h7a3.dtsi:110 */
		octospi2: spi@5200a000 {
			compatible = "st,stm32-ospi";    /* in zephyr/dts/arm/st/h7/stm32h7a3.dtsi:111 */
			reg = < 0x5200a000 0x1000 >,
			      < 0x70000000 0x10000000 >; /* in zephyr/dts/arm/st/h7/stm32h7a3.dtsi:112 */
			interrupts = < 0x96 0x0 >;       /* in zephyr/dts/arm/st/h7/stm32h7a3.dtsi:113 */
			clock-names = "ospix",
			              "ospi-ker";        /* in zephyr/dts/arm/st/h7/stm32h7a3.dtsi:114 */
			clocks = < &rcc 0xd4 0x80000 >,
			         < &rcc 0x9 0x124004c >; /* in zephyr/dts/arm/st/h7/stm32h7a3.dtsi:115 */
			#address-cells = < 0x1 >;        /* in zephyr/dts/arm/st/h7/stm32h7a3.dtsi:117 */
			#size-cells = < 0x0 >;           /* in zephyr/dts/arm/st/h7/stm32h7a3.dtsi:118 */
			status = "disabled";             /* in zephyr/dts/arm/st/h7/stm32h7a3.dtsi:119 */
		};

		/* node '/soc/i2s@58001400' defined in zephyr/dts/arm/st/h7/stm32h7a3.dtsi:122 */
		i2s6: i2s@58001400 {
			compatible = "st,stm32h7-i2s",
			             "st,stm32-i2s";         /* in zephyr/dts/arm/st/h7/stm32h7a3.dtsi:123 */
			#address-cells = < 0x1 >;            /* in zephyr/dts/arm/st/h7/stm32h7a3.dtsi:124 */
			#size-cells = < 0x0 >;               /* in zephyr/dts/arm/st/h7/stm32h7a3.dtsi:125 */
			reg = < 0x58001400 0x400 >;          /* in zephyr/dts/arm/st/h7/stm32h7a3.dtsi:126 */
			clocks = < &rcc 0xf4 0x20 >,
			         < &rcc 0x9 0x5c0058 >;      /* in zephyr/dts/arm/st/h7/stm32h7a3.dtsi:127 */
			dmas = < &dmamux2 0x0 0xc 0x20440 >,
			       < &dmamux2 0x1 0xb 0x20480 >; /* in zephyr/dts/arm/st/h7/stm32h7a3.dtsi:129 */
			dma-names = "tx",
			            "rx";                    /* in zephyr/dts/arm/st/h7/stm32h7a3.dtsi:131 */
			interrupts = < 0x56 0x0 >;           /* in zephyr/dts/arm/st/h7/stm32h7a3.dtsi:132 */
			status = "disabled";                 /* in zephyr/dts/arm/st/h7/stm32h7a3.dtsi:133 */
		};

		/* node '/soc/digi_dietemp@58006800' defined in zephyr/dts/arm/st/h7/stm32h7a3.dtsi:142 */
		digi_die_temp: digi_dietemp@58006800 {
			compatible = "st,stm32-digi-temp"; /* in zephyr/dts/arm/st/h7/stm32h7a3.dtsi:143 */
			reg = < 0x58006800 0x400 >;        /* in zephyr/dts/arm/st/h7/stm32h7a3.dtsi:144 */
			interrupts = < 0x93 0x0 >;         /* in zephyr/dts/arm/st/h7/stm32h7a3.dtsi:145 */
			interrupt-names = "digi_temp";     /* in zephyr/dts/arm/st/h7/stm32h7a3.dtsi:146 */
			clocks = < &rcc 0xf4 0x4000000 >;  /* in zephyr/dts/arm/st/h7/stm32h7a3.dtsi:147 */
			status = "disabled";               /* in zephyr/dts/arm/st/h7/stm32h7a3.dtsi:148 */
		};

		/* node '/soc/crc@40023000' defined in zephyr/dts/arm/st/h7/stm32h7a3.dtsi:151 */
		crc: crc@40023000 {
			compatible = "st,stm32-crc";  /* in zephyr/dts/arm/st/h7/stm32h7a3.dtsi:152 */
			reg = < 0x40023000 0x400 >;   /* in zephyr/dts/arm/st/h7/stm32h7a3.dtsi:153 */
			clocks = < &rcc 0xd8 0x200 >; /* in zephyr/dts/arm/st/h7/stm32h7a3.dtsi:154 */
			resets = < &rctl 0x1009 >;    /* in zephyr/dts/arm/st/h7/stm32h7a3.dtsi:155 */
			status = "disabled";          /* in zephyr/dts/arm/st/h7/stm32h7a3.dtsi:156 */
		};

		/* node '/soc/cryp@48021000' defined in zephyr/dts/arm/st/h7/stm32h7b0.dtsi:17 */
		cryp: cryp@48021000 {
			compatible = "st,stm32-cryp"; /* in zephyr/dts/arm/st/h7/stm32h7b0.dtsi:18 */
			reg = < 0x48021000 0x400 >;   /* in zephyr/dts/arm/st/h7/stm32h7b0.dtsi:19 */
			clocks = < &rcc 0xdc 0x10 >;  /* in zephyr/dts/arm/st/h7/stm32h7b0.dtsi:20 */
			resets = < &rctl 0x1084 >;    /* in zephyr/dts/arm/st/h7/stm32h7b0.dtsi:21 */
			interrupts = < 0x4f 0x0 >;    /* in zephyr/dts/arm/st/h7/stm32h7b0.dtsi:22 */
			interrupt-names = "cryp";     /* in zephyr/dts/arm/st/h7/stm32h7b0.dtsi:23 */
			status = "disabled";          /* in zephyr/dts/arm/st/h7/stm32h7b0.dtsi:24 */
		};

		/* node '/soc/hash@48021400' defined in zephyr/dts/arm/st/h7/stm32h7b0.dtsi:27 */
		hash: hash@48021400 {
			compatible = "st,stm32-hash"; /* in zephyr/dts/arm/st/h7/stm32h7b0.dtsi:28 */
			reg = < 0x48021400 0x400 >;   /* in zephyr/dts/arm/st/h7/stm32h7b0.dtsi:29 */
			clocks = < &rcc 0xdc 0x20 >;  /* in zephyr/dts/arm/st/h7/stm32h7b0.dtsi:30 */
			resets = < &rctl 0x1085 >;    /* in zephyr/dts/arm/st/h7/stm32h7b0.dtsi:31 */
			interrupts = < 0x50 0x0 >;    /* in zephyr/dts/arm/st/h7/stm32h7b0.dtsi:32 */
			status = "disabled";          /* in zephyr/dts/arm/st/h7/stm32h7b0.dtsi:33 */
		};
	};

	/* node '/cpus' defined in zephyr/dts/arm/st/h7/stm32h7.dtsi:34 */
	cpus {
		#address-cells = < 0x1 >; /* in zephyr/dts/arm/st/h7/stm32h7.dtsi:35 */
		#size-cells = < 0x0 >;    /* in zephyr/dts/arm/st/h7/stm32h7.dtsi:36 */

		/* node '/cpus/cpu@0' defined in zephyr/dts/arm/st/h7/stm32h7.dtsi:38 */
		cpu0: cpu@0 {
			device_type = "cpu";          /* in zephyr/dts/arm/st/h7/stm32h7.dtsi:39 */
			compatible = "arm,cortex-m7"; /* in zephyr/dts/arm/st/h7/stm32h7.dtsi:40 */
			reg = < 0x0 >;                /* in zephyr/dts/arm/st/h7/stm32h7.dtsi:41 */
			#address-cells = < 0x1 >;     /* in zephyr/dts/arm/st/h7/stm32h7.dtsi:42 */
			#size-cells = < 0x1 >;        /* in zephyr/dts/arm/st/h7/stm32h7.dtsi:43 */

			/* node '/cpus/cpu@0/mpu@e000ed90' defined in zephyr/dts/arm/st/h7/stm32h7.dtsi:45 */
			mpu: mpu@e000ed90 {
				compatible = "arm,armv7m-mpu"; /* in zephyr/dts/arm/st/h7/stm32h7.dtsi:46 */
				reg = < 0xe000ed90 0x40 >;     /* in zephyr/dts/arm/st/h7/stm32h7.dtsi:47 */
			};
		};
	};

	/* node '/memory@0' defined in zephyr/dts/arm/st/h7/stm32h7.dtsi:52 */
	itcm: memory@0 {
		compatible = "zephyr,memory-region",
		             "arm,itcm";             /* in zephyr/dts/arm/st/h7/stm32h7.dtsi:53 */
		reg = < 0x0 0x10000 >;               /* in zephyr/dts/arm/st/h7/stm32h7.dtsi:54 */
		zephyr,memory-region = "ITCM";       /* in zephyr/dts/arm/st/h7/stm32h7.dtsi:55 */
	};

	/* node '/memory@20000000' defined in zephyr/dts/arm/st/h7/stm32h7.dtsi:58 */
	dtcm: memory@20000000 {
		compatible = "zephyr,memory-region",
		             "arm,dtcm";             /* in zephyr/dts/arm/st/h7/stm32h7.dtsi:59 */
		reg = < 0x20000000 0x20000 >;        /* in zephyr/dts/arm/st/h7/stm32h7.dtsi:60 */
		zephyr,memory-region = "DTCM";       /* in zephyr/dts/arm/st/h7/stm32h7.dtsi:61 */
	};

	/* node '/memory@90000000' defined in zephyr/dts/arm/st/h7/stm32h7.dtsi:64 */
	ext_memory: memory@90000000 {
		compatible = "zephyr,memory-region"; /* in zephyr/dts/arm/st/h7/stm32h7.dtsi:65 */
		reg = < 0x90000000 0x10000000 >;     /* in zephyr/dts/arm/st/h7/stm32h7.dtsi:66 */
		zephyr,memory-region = "EXTMEM";     /* in zephyr/dts/arm/st/h7/stm32h7.dtsi:67 */
		zephyr,memory-attr = < 0x2000000 >;  /* in zephyr/dts/arm/st/h7/stm32h7.dtsi:68 */
	};

	/* node '/clocks' defined in zephyr/dts/arm/st/h7/stm32h7.dtsi:71 */
	clocks {
		#address-cells = < 0x1 >; /* in zephyr/dts/arm/st/h7/stm32h7.dtsi:72 */
		#size-cells = < 0x0 >;    /* in zephyr/dts/arm/st/h7/stm32h7.dtsi:73 */

		/* node '/clocks/clk-hse' defined in zephyr/dts/arm/st/h7/stm32h7.dtsi:75 */
		clk_hse: clk-hse {
			#clock-cells = < 0x0 >;            /* in zephyr/dts/arm/st/h7/stm32h7.dtsi:76 */
			compatible = "st,stm32-hse-clock"; /* in zephyr/dts/arm/st/h7/stm32h7.dtsi:77 */
			clock-frequency = < 0x17d7840 >;   /* in zephyr/boards/weact/mini_stm32h7b0/mini_stm32h7b0.dts:97 */
			status = "okay";                   /* in zephyr/boards/weact/mini_stm32h7b0/mini_stm32h7b0.dts:98 */
			phandle = < 0x1f >;                /* in zephyr/boards/weact/mini_stm32h7b0/mini_stm32h7b0.dts:107 */
		};

		/* node '/clocks/clk-hsi' defined in zephyr/dts/arm/st/h7/stm32h7.dtsi:82 */
		clk_hsi: clk-hsi {
			#clock-cells = < 0x0 >;              /* in zephyr/dts/arm/st/h7/stm32h7.dtsi:83 */
			compatible = "st,stm32h7-hsi-clock"; /* in zephyr/dts/arm/st/h7/stm32h7.dtsi:84 */
			hsi-div = < 0x1 >;                   /* in zephyr/dts/arm/st/h7/stm32h7.dtsi:85 */
			clock-frequency = < 0x3d09000 >;     /* in zephyr/dts/arm/st/h7/stm32h7.dtsi:86 */
			status = "disabled";                 /* in zephyr/dts/arm/st/h7/stm32h7.dtsi:87 */
		};

		/* node '/clocks/clk-hsi48' defined in zephyr/dts/arm/st/h7/stm32h7.dtsi:90 */
		clk_hsi48: clk-hsi48 {
			#clock-cells = < 0x0 >;          /* in zephyr/dts/arm/st/h7/stm32h7.dtsi:91 */
			compatible = "fixed-clock";      /* in zephyr/dts/arm/st/h7/stm32h7.dtsi:92 */
			clock-frequency = < 0x2dc6c00 >; /* in zephyr/dts/arm/st/h7/stm32h7.dtsi:93 */
			status = "okay";                 /* in zephyr/boards/weact/mini_stm32h7b0/mini_stm32h7b0.dts:93 */
		};

		/* node '/clocks/clk-csi' defined in zephyr/dts/arm/st/h7/stm32h7.dtsi:97 */
		clk_csi: clk-csi {
			#clock-cells = < 0x0 >;         /* in zephyr/dts/arm/st/h7/stm32h7.dtsi:98 */
			compatible = "fixed-clock";     /* in zephyr/dts/arm/st/h7/stm32h7.dtsi:99 */
			clock-frequency = < 0x3d0900 >; /* in zephyr/dts/arm/st/h7/stm32h7.dtsi:100 */
			status = "disabled";            /* in zephyr/dts/arm/st/h7/stm32h7.dtsi:101 */
		};

		/* node '/clocks/clk-lse' defined in zephyr/dts/arm/st/h7/stm32h7.dtsi:104 */
		clk_lse: clk-lse {
			#clock-cells = < 0x0 >;            /* in zephyr/dts/arm/st/h7/stm32h7.dtsi:105 */
			compatible = "st,stm32-lse-clock"; /* in zephyr/dts/arm/st/h7/stm32h7.dtsi:106 */
			clock-frequency = < 0x8000 >;      /* in zephyr/dts/arm/st/h7/stm32h7.dtsi:107 */
			driving-capability = < 0x0 >;      /* in zephyr/dts/arm/st/h7/stm32h7.dtsi:108 */
			status = "disabled";               /* in zephyr/dts/arm/st/h7/stm32h7.dtsi:109 */
		};

		/* node '/clocks/clk-lsi' defined in zephyr/dts/arm/st/h7/stm32h7.dtsi:112 */
		clk_lsi: clk-lsi {
			#clock-cells = < 0x0 >;       /* in zephyr/dts/arm/st/h7/stm32h7.dtsi:113 */
			compatible = "fixed-clock";   /* in zephyr/dts/arm/st/h7/stm32h7.dtsi:114 */
			clock-frequency = < 0x7d00 >; /* in zephyr/dts/arm/st/h7/stm32h7.dtsi:115 */
			status = "okay";              /* in zephyr/boards/weact/mini_stm32h7b0/mini_stm32h7b0.dts:89 */
		};

		/* node '/clocks/pll@0' defined in zephyr/dts/arm/st/h7/stm32h7.dtsi:119 */
		pll: pll@0 {
			#clock-cells = < 0x0 >;              /* in zephyr/dts/arm/st/h7/stm32h7.dtsi:120 */
			compatible = "st,stm32h7-pll-clock"; /* in zephyr/dts/arm/st/h7/stm32h7.dtsi:121 */
			reg = < 0x0 >;                       /* in zephyr/dts/arm/st/h7/stm32h7.dtsi:122 */
			div-m = < 0x5 >;                     /* in zephyr/boards/weact/mini_stm32h7b0/mini_stm32h7b0.dts:102 */
			mul-n = < 0x70 >;                    /* in zephyr/boards/weact/mini_stm32h7b0/mini_stm32h7b0.dts:103 */
			div-p = < 0x2 >;                     /* in zephyr/boards/weact/mini_stm32h7b0/mini_stm32h7b0.dts:104 */
			div-q = < 0x2 >;                     /* in zephyr/boards/weact/mini_stm32h7b0/mini_stm32h7b0.dts:105 */
			div-r = < 0x2 >;                     /* in zephyr/boards/weact/mini_stm32h7b0/mini_stm32h7b0.dts:106 */
			clocks = < &clk_hse >;               /* in zephyr/boards/weact/mini_stm32h7b0/mini_stm32h7b0.dts:107 */
			status = "okay";                     /* in zephyr/boards/weact/mini_stm32h7b0/mini_stm32h7b0.dts:108 */
			phandle = < 0x2 >;                   /* in zephyr/boards/weact/mini_stm32h7b0/mini_stm32h7b0.dts:112 */
		};

		/* node '/clocks/pll@1' defined in zephyr/dts/arm/st/h7/stm32h7.dtsi:126 */
		pll2: pll@1 {
			#clock-cells = < 0x0 >;              /* in zephyr/dts/arm/st/h7/stm32h7.dtsi:127 */
			compatible = "st,stm32h7-pll-clock"; /* in zephyr/dts/arm/st/h7/stm32h7.dtsi:128 */
			reg = < 0x1 >;                       /* in zephyr/dts/arm/st/h7/stm32h7.dtsi:129 */
			status = "disabled";                 /* in zephyr/dts/arm/st/h7/stm32h7.dtsi:130 */
		};

		/* node '/clocks/pll@2' defined in zephyr/dts/arm/st/h7/stm32h7.dtsi:133 */
		pll3: pll@2 {
			#clock-cells = < 0x0 >;              /* in zephyr/dts/arm/st/h7/stm32h7.dtsi:134 */
			compatible = "st,stm32h7-pll-clock"; /* in zephyr/dts/arm/st/h7/stm32h7.dtsi:135 */
			reg = < 0x2 >;                       /* in zephyr/dts/arm/st/h7/stm32h7.dtsi:136 */
			status = "disabled";                 /* in zephyr/dts/arm/st/h7/stm32h7.dtsi:137 */
		};

		/* node '/clocks/perck' defined in zephyr/dts/arm/st/h7/stm32h7.dtsi:140 */
		perck: perck {
			#clock-cells = < 0x0 >;            /* in zephyr/dts/arm/st/h7/stm32h7.dtsi:141 */
			compatible = "st,stm32-clock-mux"; /* in zephyr/dts/arm/st/h7/stm32h7.dtsi:142 */
			status = "disabled";               /* in zephyr/dts/arm/st/h7/stm32h7.dtsi:143 */
		};
	};

	/* node '/mcos' defined in zephyr/dts/arm/st/h7/stm32h7.dtsi:147 */
	mcos {

		/* node '/mcos/mco1' defined in zephyr/dts/arm/st/h7/stm32h7.dtsi:148 */
		mco1: mco1 {
			compatible = "st,stm32-clock-mco"; /* in zephyr/dts/arm/st/h7/stm32h7.dtsi:149 */
			clock-names = "clksel";            /* in zephyr/dts/arm/st/h7/stm32h7.dtsi:150 */
			status = "disabled";               /* in zephyr/dts/arm/st/h7/stm32h7.dtsi:151 */
		};

		/* node '/mcos/mco2' defined in zephyr/dts/arm/st/h7/stm32h7.dtsi:154 */
		mco2: mco2 {
			compatible = "st,stm32-clock-mco"; /* in zephyr/dts/arm/st/h7/stm32h7.dtsi:155 */
			clock-names = "clksel";            /* in zephyr/dts/arm/st/h7/stm32h7.dtsi:156 */
			status = "disabled";               /* in zephyr/dts/arm/st/h7/stm32h7.dtsi:157 */
		};
	};

	/* node '/dietemp' defined in zephyr/dts/arm/st/h7/stm32h7.dtsi:1344 */
	die_temp: dietemp {
		compatible = "st,stm32-temp-cal"; /* in zephyr/dts/arm/st/h7/stm32h7.dtsi:1345 */
		nvmem-cells = < &ts_cal1_otp >,
		              < &ts_cal2_otp >;   /* in zephyr/dts/arm/st/h7/stm32h7.dtsi:1346 */
		nvmem-cell-names = "TS_CAL1",
		                   "TS_CAL2";     /* in zephyr/dts/arm/st/h7/stm32h7.dtsi:1347 */
		ts-cal1-temp = < 0x1e >;          /* in zephyr/dts/arm/st/h7/stm32h7.dtsi:1348 */
		ts-cal-vrefanalog = < 0xce4 >;    /* in zephyr/dts/arm/st/h7/stm32h7.dtsi:1350 */
		ts-cal-resolution = < 0x10 >;     /* in zephyr/dts/arm/st/h7/stm32h7.dtsi:1351 */
		status = "disabled";              /* in zephyr/dts/arm/st/h7/stm32h7.dtsi:1353 */
		io-channels = < &adc2 0x12 >;     /* in zephyr/dts/arm/st/h7/stm32h7a3.dtsi:217 */
		ts-cal2-temp = < 0x82 >;          /* in zephyr/dts/arm/st/h7/stm32h7a3.dtsi:218 */
	};

	/* node '/vbat' defined in zephyr/dts/arm/st/h7/stm32h7.dtsi:1356 */
	vbat: vbat {
		compatible = "st,stm32-vbat"; /* in zephyr/dts/arm/st/h7/stm32h7.dtsi:1357 */
		ratio = < 0x4 >;              /* in zephyr/dts/arm/st/h7/stm32h7.dtsi:1358 */
		status = "disabled";          /* in zephyr/dts/arm/st/h7/stm32h7.dtsi:1359 */
		io-channels = < &adc2 0xe >;  /* in zephyr/dts/arm/st/h7/stm32h7a3.dtsi:226 */
	};

	/* node '/vref' defined in zephyr/dts/arm/st/h7/stm32h7.dtsi:1362 */
	vref: vref {
		compatible = "st,stm32-vref";      /* in zephyr/dts/arm/st/h7/stm32h7.dtsi:1363 */
		nvmem-cells = < &vrefint_otp >;    /* in zephyr/dts/arm/st/h7/stm32h7.dtsi:1364 */
		vrefint-cal-mv = < 0xce4 >;        /* in zephyr/dts/arm/st/h7/stm32h7.dtsi:1365 */
		vrefint-cal-resolution = < 0x10 >; /* in zephyr/dts/arm/st/h7/stm32h7.dtsi:1366 */
		status = "disabled";               /* in zephyr/dts/arm/st/h7/stm32h7.dtsi:1367 */
		io-channels = < &adc2 0x13 >;      /* in zephyr/dts/arm/st/h7/stm32h7a3.dtsi:222 */
	};

	/* node '/smbus1' defined in zephyr/dts/arm/st/h7/stm32h7.dtsi:1370 */
	smbus1: smbus1 {
		compatible = "st,stm32-smbus"; /* in zephyr/dts/arm/st/h7/stm32h7.dtsi:1371 */
		#address-cells = < 0x1 >;      /* in zephyr/dts/arm/st/h7/stm32h7.dtsi:1372 */
		#size-cells = < 0x0 >;         /* in zephyr/dts/arm/st/h7/stm32h7.dtsi:1373 */
		i2c = < &i2c1 >;               /* in zephyr/dts/arm/st/h7/stm32h7.dtsi:1374 */
		status = "disabled";           /* in zephyr/dts/arm/st/h7/stm32h7.dtsi:1375 */
	};

	/* node '/smbus2' defined in zephyr/dts/arm/st/h7/stm32h7.dtsi:1378 */
	smbus2: smbus2 {
		compatible = "st,stm32-smbus"; /* in zephyr/dts/arm/st/h7/stm32h7.dtsi:1379 */
		#address-cells = < 0x1 >;      /* in zephyr/dts/arm/st/h7/stm32h7.dtsi:1380 */
		#size-cells = < 0x0 >;         /* in zephyr/dts/arm/st/h7/stm32h7.dtsi:1381 */
		i2c = < &i2c2 >;               /* in zephyr/dts/arm/st/h7/stm32h7.dtsi:1382 */
		status = "disabled";           /* in zephyr/dts/arm/st/h7/stm32h7.dtsi:1383 */
	};

	/* node '/smbus3' defined in zephyr/dts/arm/st/h7/stm32h7.dtsi:1386 */
	smbus3: smbus3 {
		compatible = "st,stm32-smbus"; /* in zephyr/dts/arm/st/h7/stm32h7.dtsi:1387 */
		#address-cells = < 0x1 >;      /* in zephyr/dts/arm/st/h7/stm32h7.dtsi:1388 */
		#size-cells = < 0x0 >;         /* in zephyr/dts/arm/st/h7/stm32h7.dtsi:1389 */
		i2c = < &i2c3 >;               /* in zephyr/dts/arm/st/h7/stm32h7.dtsi:1390 */
		status = "disabled";           /* in zephyr/dts/arm/st/h7/stm32h7.dtsi:1391 */
	};

	/* node '/smbus4' defined in zephyr/dts/arm/st/h7/stm32h7.dtsi:1394 */
	smbus4: smbus4 {
		compatible = "st,stm32-smbus"; /* in zephyr/dts/arm/st/h7/stm32h7.dtsi:1395 */
		#address-cells = < 0x1 >;      /* in zephyr/dts/arm/st/h7/stm32h7.dtsi:1396 */
		#size-cells = < 0x0 >;         /* in zephyr/dts/arm/st/h7/stm32h7.dtsi:1397 */
		i2c = < &i2c4 >;               /* in zephyr/dts/arm/st/h7/stm32h7.dtsi:1398 */
		status = "disabled";           /* in zephyr/dts/arm/st/h7/stm32h7.dtsi:1399 */
	};

	/* node '/memory@24000000' defined in zephyr/dts/arm/st/h7/stm32h7a3.dtsi:161 */
	sram0: memory@24000000 {
		compatible = "zephyr,memory-region",
		             "mmio-sram";            /* in zephyr/dts/arm/st/h7/stm32h7a3.dtsi:162 */
		reg = < 0x24000000 0x40000 >;        /* in zephyr/dts/arm/st/h7/stm32h7a3.dtsi:163 */
		zephyr,memory-region = "SRAM0";      /* in zephyr/dts/arm/st/h7/stm32h7a3.dtsi:164 */
	};

	/* node '/memory@24040000' defined in zephyr/dts/arm/st/h7/stm32h7a3.dtsi:168 */
	sram1: memory@24040000 {
		compatible = "zephyr,memory-region",
		             "mmio-sram";            /* in zephyr/dts/arm/st/h7/stm32h7a3.dtsi:169 */
		reg = < 0x24040000 0x60000 >;        /* in zephyr/dts/arm/st/h7/stm32h7a3.dtsi:170 */
		zephyr,memory-region = "SRAM1";      /* in zephyr/dts/arm/st/h7/stm32h7a3.dtsi:171 */
	};

	/* node '/memory@240a0000' defined in zephyr/dts/arm/st/h7/stm32h7a3.dtsi:175 */
	sram2: memory@240a0000 {
		compatible = "zephyr,memory-region",
		             "mmio-sram";            /* in zephyr/dts/arm/st/h7/stm32h7a3.dtsi:176 */
		reg = < 0x240a0000 0x60000 >;        /* in zephyr/dts/arm/st/h7/stm32h7a3.dtsi:177 */
		zephyr,memory-region = "SRAM2";      /* in zephyr/dts/arm/st/h7/stm32h7a3.dtsi:178 */
		#memory-region-cells = < 0x0 >;      /* in zephyr/dts/arm/st/h7/stm32h7a3.dtsi:179 */
	};

	/* node '/memory@30000000' defined in zephyr/dts/arm/st/h7/stm32h7a3.dtsi:183 */
	sram3: memory@30000000 {
		compatible = "zephyr,memory-region",
		             "mmio-sram";            /* in zephyr/dts/arm/st/h7/stm32h7a3.dtsi:184 */
		reg = < 0x30000000 0x10000 >;        /* in zephyr/dts/arm/st/h7/stm32h7a3.dtsi:185 */
		zephyr,memory-region = "SRAM3";      /* in zephyr/dts/arm/st/h7/stm32h7a3.dtsi:186 */
		#memory-region-cells = < 0x0 >;      /* in zephyr/dts/arm/st/h7/stm32h7a3.dtsi:187 */
		phandle = < 0x13 >;                  /* in zephyr/dts/arm/st/h7/stm32h7a3.dtsi:269 */
	};

	/* node '/memory@30010000' defined in zephyr/dts/arm/st/h7/stm32h7a3.dtsi:191 */
	sram4: memory@30010000 {
		compatible = "zephyr,memory-region",
		             "mmio-sram";            /* in zephyr/dts/arm/st/h7/stm32h7a3.dtsi:192 */
		reg = < 0x30010000 0x10000 >;        /* in zephyr/dts/arm/st/h7/stm32h7a3.dtsi:193 */
		zephyr,memory-region = "SRAM4";      /* in zephyr/dts/arm/st/h7/stm32h7a3.dtsi:194 */
	};

	/* node '/memory@38000000' defined in zephyr/dts/arm/st/h7/stm32h7a3.dtsi:198 */
	sram5: memory@38000000 {
		compatible = "zephyr,memory-region",
		             "mmio-sram";            /* in zephyr/dts/arm/st/h7/stm32h7a3.dtsi:199 */
		reg = < 0x38000000 0x8000 >;         /* in zephyr/dts/arm/st/h7/stm32h7a3.dtsi:200 */
		zephyr,memory-region = "SRAM5";      /* in zephyr/dts/arm/st/h7/stm32h7a3.dtsi:201 */
	};

	/* node '/memory@70000000' defined in zephyr/dts/arm/st/h7/stm32h7a3.dtsi:204 */
	ext_memory2: memory@70000000 {
		compatible = "zephyr,memory-region"; /* in zephyr/dts/arm/st/h7/stm32h7a3.dtsi:205 */
		reg = < 0x70000000 0x10000000 >;     /* in zephyr/dts/arm/st/h7/stm32h7a3.dtsi:206 */
		zephyr,memory-region = "EXTMEM2";    /* in zephyr/dts/arm/st/h7/stm32h7a3.dtsi:207 */
		zephyr,memory-attr = < 0x2000000 >;  /* in zephyr/dts/arm/st/h7/stm32h7a3.dtsi:208 */
	};

	/* node '/otghs_fs_phy' defined in zephyr/dts/arm/st/h7/stm32h7a3.dtsi:211 */
	otghs_fs_phy: otghs_fs_phy {
		compatible = "usb-nop-xceiv"; /* in zephyr/dts/arm/st/h7/stm32h7a3.dtsi:212 */
		#phy-cells = < 0x0 >;         /* in zephyr/dts/arm/st/h7/stm32h7a3.dtsi:213 */
		phandle = < 0x1b >;           /* in zephyr/dts/arm/st/h7/stm32h7a3.dtsi:84 */
	};

	/* node '/leds' defined in zephyr/boards/weact/mini_stm32h7b0/mini_stm32h7b0.dts:23 */
	leds {
		compatible = "gpio-leds"; /* in zephyr/boards/weact/mini_stm32h7b0/mini_stm32h7b0.dts:24 */

		/* node '/leds/led' defined in zephyr/boards/weact/mini_stm32h7b0/mini_stm32h7b0.dts:26 */
		user_led: led {
			gpios = < &gpioe 0x3 0x0 >; /* in zephyr/boards/weact/mini_stm32h7b0/mini_stm32h7b0.dts:27 */
			label = "User LED";         /* in zephyr/boards/weact/mini_stm32h7b0/mini_stm32h7b0.dts:28 */
		};
	};

	/* node '/gpio_keys' defined in zephyr/boards/weact/mini_stm32h7b0/mini_stm32h7b0.dts:32 */
	gpio_keys {
		compatible = "gpio-keys"; /* in zephyr/boards/weact/mini_stm32h7b0/mini_stm32h7b0.dts:33 */

		/* node '/gpio_keys/button' defined in zephyr/boards/weact/mini_stm32h7b0/mini_stm32h7b0.dts:35 */
		user_button: button {
			label = "User PB";           /* in zephyr/boards/weact/mini_stm32h7b0/mini_stm32h7b0.dts:36 */
			gpios = < &gpioc 0xd 0x20 >; /* in zephyr/boards/weact/mini_stm32h7b0/mini_stm32h7b0.dts:37 */
			zephyr,code = < 0xb >;       /* in zephyr/boards/weact/mini_stm32h7b0/mini_stm32h7b0.dts:38 */
		};
	};

	/* node '/mipi_dbi_st7735r_160x80' defined in zephyr/boards/weact/mini_stm32h7b0/mini_stm32h7b0.dts:42 */
	mipi_dbi_st7735r_160x80 {
		compatible = "zephyr,mipi-dbi-spi"; /* in zephyr/boards/weact/mini_stm32h7b0/mini_stm32h7b0.dts:43 */
		spi-dev = < &spi4 >;                /* in zephyr/boards/weact/mini_stm32h7b0/mini_stm32h7b0.dts:44 */
		dc-gpios = < &gpioe 0xd 0x0 >;      /* in zephyr/boards/weact/mini_stm32h7b0/mini_stm32h7b0.dts:45 */
		#address-cells = < 0x1 >;           /* in zephyr/boards/weact/mini_stm32h7b0/mini_stm32h7b0.dts:46 */
		#size-cells = < 0x0 >;              /* in zephyr/boards/weact/mini_stm32h7b0/mini_stm32h7b0.dts:47 */

		/* node '/mipi_dbi_st7735r_160x80/st7735r@0' defined in zephyr/boards/weact/mini_stm32h7b0/mini_stm32h7b0.dts:49 */
		st7735r_160x80: st7735r@0 {
			compatible = "sitronix,st7735r";                                /* in zephyr/boards/weact/mini_stm32h7b0/mini_stm32h7b0.dts:50 */
			mipi-max-frequency = < 0x1312d00 >;                             /* in zephyr/boards/weact/mini_stm32h7b0/mini_stm32h7b0.dts:51 */
			mipi-mode = "MIPI_DBI_MODE_SPI_4WIRE";                          /* in zephyr/boards/weact/mini_stm32h7b0/mini_stm32h7b0.dts:52 */
			reg = < 0x0 >;                                                  /* in zephyr/boards/weact/mini_stm32h7b0/mini_stm32h7b0.dts:53 */
			width = < 0xa0 >;                                               /* in zephyr/boards/weact/mini_stm32h7b0/mini_stm32h7b0.dts:54 */
			height = < 0x50 >;                                              /* in zephyr/boards/weact/mini_stm32h7b0/mini_stm32h7b0.dts:55 */
			inversion-on;                                                   /* in zephyr/boards/weact/mini_stm32h7b0/mini_stm32h7b0.dts:56 */
			rgb-is-inverted;                                                /* in zephyr/boards/weact/mini_stm32h7b0/mini_stm32h7b0.dts:57 */
			x-offset = < 0x1 >;                                             /* in zephyr/boards/weact/mini_stm32h7b0/mini_stm32h7b0.dts:58 */
			y-offset = < 0x1a >;                                            /* in zephyr/boards/weact/mini_stm32h7b0/mini_stm32h7b0.dts:59 */
			pwctr1 = [ A2 02 84 ];                                          /* in zephyr/boards/weact/mini_stm32h7b0/mini_stm32h7b0.dts:60 */
			pwctr2 = [ C5 ];                                                /* in zephyr/boards/weact/mini_stm32h7b0/mini_stm32h7b0.dts:61 */
			pwctr3 = [ 0A 00 ];                                             /* in zephyr/boards/weact/mini_stm32h7b0/mini_stm32h7b0.dts:62 */
			pwctr4 = [ 8A 2A ];                                             /* in zephyr/boards/weact/mini_stm32h7b0/mini_stm32h7b0.dts:63 */
			pwctr5 = [ 8A EE ];                                             /* in zephyr/boards/weact/mini_stm32h7b0/mini_stm32h7b0.dts:64 */
			invctr = < 0x7 >;                                               /* in zephyr/boards/weact/mini_stm32h7b0/mini_stm32h7b0.dts:65 */
			frmctr1 = [ 01 2C 2D ];                                         /* in zephyr/boards/weact/mini_stm32h7b0/mini_stm32h7b0.dts:66 */
			frmctr2 = [ 01 2C 2D ];                                         /* in zephyr/boards/weact/mini_stm32h7b0/mini_stm32h7b0.dts:67 */
			frmctr3 = [ 01 2C 2D 01 2C 2D ];                                /* in zephyr/boards/weact/mini_stm32h7b0/mini_stm32h7b0.dts:68 */
			vmctr1 = < 0xe >;                                               /* in zephyr/boards/weact/mini_stm32h7b0/mini_stm32h7b0.dts:69 */
			gamctrp1 = [ 02 1C 07 12 37 32 29 2D 29 25 2B 39 00 01 03 10 ]; /* in zephyr/boards/weact/mini_stm32h7b0/mini_stm32h7b0.dts:70 */
			gamctrn1 = [ 03 1D 07 06 2E 2C 29 2D 2E 2E 37 3F 00 00 02 10 ]; /* in zephyr/boards/weact/mini_stm32h7b0/mini_stm32h7b0.dts:71 */
			colmod = < 0x5 >;                                               /* in zephyr/boards/weact/mini_stm32h7b0/mini_stm32h7b0.dts:72 */
			madctl = < 0x78 >;                                              /* in zephyr/boards/weact/mini_stm32h7b0/mini_stm32h7b0.dts:74 */
			caset = [ 00 01 00 A0 ];                                        /* in zephyr/boards/weact/mini_stm32h7b0/mini_stm32h7b0.dts:75 */
			raset = [ 00 1A 00 69 ];                                        /* in zephyr/boards/weact/mini_stm32h7b0/mini_stm32h7b0.dts:76 */
		};
	};
};
